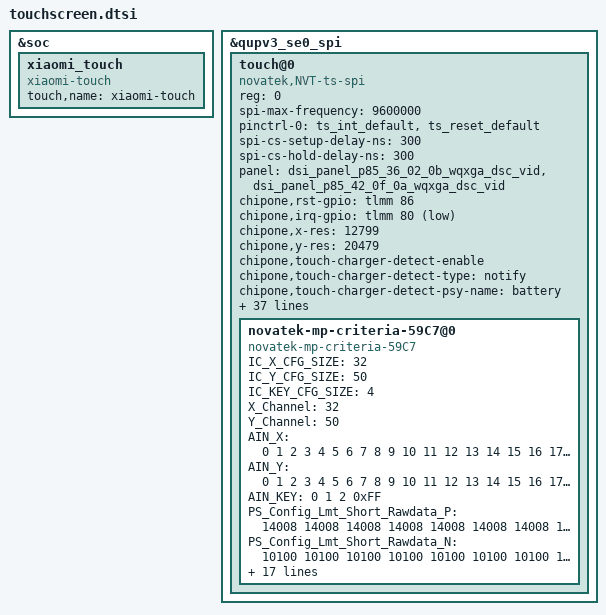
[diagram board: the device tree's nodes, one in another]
/*
 * Copyright (C) 2025 Novatek, Inc.
 *
 * $Revision$
 * $Date$
 *
 * This program is free software; you can redistribute it and/or modify
 * it under the terms of the GNU General Public License as published by
 * the Free Software Foundation; either version 2 of the License, or
 * (at your option) any later version.
 *
 * This program is distributed in the hope that it will be useful, but WITHOUT
 * ANY WARRANTY; without even the implied warranty of MERCHANTABILITY or
 * FITNESS FOR A PARTICULAR PURPOSE.  See the GNU General Public License for
 * more details.
 *
 */

&soc {
	xiaomi_touch {
		status = "okay";
		compatible = "xiaomi-touch";
		touch,name = "xiaomi-touch";
	};
};

&qupv3_se0_spi {
	status = "ok";

	/* Novatek device tree node */
	touch@0 {
		compatible = "novatek,NVT-ts-spi", "chipone-tddi";
		reg = <0>; //Same as CS ID
		status = "ok";

		spi-max-frequency = <9600000>;	//4800000,9600000,15000000,19200000
		pinctrl-names = "default";
		pinctrl-0 = <&ts_int_default>, <&ts_reset_default>;
		spi-cs-setup-delay-ns = <300>;
		spi-cs-hold-delay-ns = <300>;
		panel = <&dsi_panel_p85_36_02_0b_wqxga_dsc_vid &dsi_panel_p85_42_0f_0a_wqxga_dsc_vid>;

		/* chipone_icnl9951c */
		chipone,rst-gpio = <&tlmm 86 0x00>;
		chipone,irq-gpio = <&tlmm 80 0x2001>;
		//chipone,cs-gpio = <&tlmm 8 0>;
		chipone,x-res = <12799>;
		chipone,y-res = <20479>;

		/* Charger detect */
		chipone,touch-charger-detect-enable;
		chipone,touch-charger-detect-type = "notify"; /* notify, poll */
		chipone,touch-charger-detect-psy-name = "battery";
		chipone,touch-charger-detect-psp = "POWER_SUPPLY_PROP_STATUS";
		chipone,touch-charger-detect-psp-poll-interval = <1000>;

		/* Earjack detect */
		//chipone,touch-earjack-detect-enable;
		/* MTK:  /sys/bus/platform/drivers/Accdet_Driver/state,
		   Sprd: /sys/kernel/headset/state
		   QCOM: None, and disable it */
		//chipone,touch-earjack-state-filepath = "/sys/bus/platform/drivers/Accdet_Driver/state";
		//chipone,touch-earjack-poll-interval = <1000>;

		/* For tp selftest */
		chipone,test-reset-pin;
		chipone,test-int-pin;
		chipone,test-rawdata;
		chipone,test-rawdata-frames	  = <1>;
		chipone,rawdata-min			  = <1092>;
		chipone,rawdata-max			  = <3050>;
		chipone,test-noise;
		chipone,test-noise-frames		= <50>;
		chipone,noise-max				= <150>;
		chipone,test-open;
		chipone,open-min				 = <1750>;
		chipone,test-short;
		chipone,short-min				= <1550>;
		chipone,test-compensate-cap;
		chipone,compensate-cap-min	   = <1>;
		chipone,compensate-cap-max	   = <127>;

		/* gesture data test */
		chipone,test-gesture-rawdata;
		chipone,test-gesture-rawdata-frames = <1>;
		chipone,gesture-rawdata-min = <100>;
		chipone,gesture-rawdata-max = <10000>;

		chipone,test-gesture-lp-rawdata;
		chipone,test-gesture-lp-rawdata-frames = <1>;
		chipone,gesture-lp-rawdata-min = <100>;
		chipone,gesture-lp-rawdata-max = <10000>;

		chipone,test-gesture-noise;
		chipone,test-gesture-noise-frames = <50>;
		chipone,gesture-noise-max = <1000>;

		chipone,test-gesture-lp-noise;
		chipone,test-gesture-lp-noise-frames = <50>;
		chipone,gesture-lp-noise-max = <1000>;

		novatek,reset-gpio = <&tlmm 86 0x00>;
		novatek,irq-gpio = <&tlmm 80 0x2001>;

		//novatek,pen-support;

		//novatek,spi-rd-fast-addr = <0x03F310>;

		/* MP */
		novatek,mp-support-dt;

		novatek-mp-criteria-59C7@0 {
			#address-cells = <1>;
			#size-cells = <0>;
			compatible = "novatek-mp-criteria-59C7";

			/* MP Config */
			IC_X_CFG_SIZE = <32>;
			IC_Y_CFG_SIZE = <50>;
			IC_KEY_CFG_SIZE = <4>;
			X_Channel = <32>;
			Y_Channel = <50>;
			AIN_X = <0 1 2 3 4 5 6 7 8 9 10 11 12 13 14 15 16 17 18 19 20 21 22 23 24 25 26 27 28 29 30 31>;
			AIN_Y = <0 1 2 3 4 5 6 7 8 9 10 11 12 13 14 15 16 17 18 19 20 21 22 23 24 25 26 27 28 29 30 31 32 33 34 35 36 37 38 39 40 41 42 43 44 45 46 47 48 49>;
			AIN_KEY = <0 1 2 0xFF>;

			/* MP Criteria */
			PS_Config_Lmt_Short_Rawdata_P = <
				14008 14008 14008 14008 14008 14008 14008 14008 14008 14008 14008 14008 14008 14008 14008 14008 14008 14008 14008 14008 14008 14008 14008 14008 14008 14008 14008 14008 14008 14008 14008 14008
				14008 14008 14008 14008 14008 14008 14008 14008 14008 14008 14008 14008 14008 14008 14008 14008 14008 14008 14008 14008 14008 14008 14008 14008 14008 14008 14008 14008 14008 14008 14008 14008
				14008 14008 14008 14008 14008 14008 14008 14008 14008 14008 14008 14008 14008 14008 14008 14008 14008 14008 14008 14008 14008 14008 14008 14008 14008 14008 14008 14008 14008 14008 14008 14008
				14008 14008 14008 14008 14008 14008 14008 14008 14008 14008 14008 14008 14008 14008 14008 14008 14008 14008 14008 14008 14008 14008 14008 14008 14008 14008 14008 14008 14008 14008 14008 14008
				14008 14008 14008 14008 14008 14008 14008 14008 14008 14008 14008 14008 14008 14008 14008 14008 14008 14008 14008 14008 14008 14008 14008 14008 14008 14008 14008 14008 14008 14008 14008 14008
				14008 14008 14008 14008 14008 14008 14008 14008 14008 14008 14008 14008 14008 14008 14008 14008 14008 14008 14008 14008 14008 14008 14008 14008 14008 14008 14008 14008 14008 14008 14008 14008
				14008 14008 14008 14008 14008 14008 14008 14008 14008 14008 14008 14008 14008 14008 14008 14008 14008 14008 14008 14008 14008 14008 14008 14008 14008 14008 14008 14008 14008 14008 14008 14008
				14008 14008 14008 14008 14008 14008 14008 14008 14008 14008 14008 14008 14008 14008 14008 14008 14008 14008 14008 14008 14008 14008 14008 14008 14008 14008 14008 14008 14008 14008 14008 14008
				14008 14008 14008 14008 14008 14008 14008 14008 14008 14008 14008 14008 14008 14008 14008 14008 14008 14008 14008 14008 14008 14008 14008 14008 14008 14008 14008 14008 14008 14008 14008 14008
				14008 14008 14008 14008 14008 14008 14008 14008 14008 14008 14008 14008 14008 14008 14008 14008 14008 14008 14008 14008 14008 14008 14008 14008 14008 14008 14008 14008 14008 14008 14008 14008
				14008 14008 14008 14008 14008 14008 14008 14008 14008 14008 14008 14008 14008 14008 14008 14008 14008 14008 14008 14008 14008 14008 14008 14008 14008 14008 14008 14008 14008 14008 14008 14008
				14008 14008 14008 14008 14008 14008 14008 14008 14008 14008 14008 14008 14008 14008 14008 14008 14008 14008 14008 14008 14008 14008 14008 14008 14008 14008 14008 14008 14008 14008 14008 14008
				14008 14008 14008 14008 14008 14008 14008 14008 14008 14008 14008 14008 14008 14008 14008 14008 14008 14008 14008 14008 14008 14008 14008 14008 14008 14008 14008 14008 14008 14008 14008 14008
				14008 14008 14008 14008 14008 14008 14008 14008 14008 14008 14008 14008 14008 14008 14008 14008 14008 14008 14008 14008 14008 14008 14008 14008 14008 14008 14008 14008 14008 14008 14008 14008
				14008 14008 14008 14008 14008 14008 14008 14008 14008 14008 14008 14008 14008 14008 14008 14008 14008 14008 14008 14008 14008 14008 14008 14008 14008 14008 14008 14008 14008 14008 14008 14008
				14008 14008 14008 14008 14008 14008 14008 14008 14008 14008 14008 14008 14008 14008 14008 14008 14008 14008 14008 14008 14008 14008 14008 14008 14008 14008 14008 14008 14008 14008 14008 14008
				14008 14008 14008 14008 14008 14008 14008 14008 14008 14008 14008 14008 14008 14008 14008 14008 14008 14008 14008 14008 14008 14008 14008 14008 14008 14008 14008 14008 14008 14008 14008 14008
				14008 14008 14008 14008 14008 14008 14008 14008 14008 14008 14008 14008 14008 14008 14008 14008 14008 14008 14008 14008 14008 14008 14008 14008 14008 14008 14008 14008 14008 14008 14008 14008
				14008 14008 14008 14008 14008 14008 14008 14008 14008 14008 14008 14008 14008 14008 14008 14008 14008 14008 14008 14008 14008 14008 14008 14008 14008 14008 14008 14008 14008 14008 14008 14008
				14008 14008 14008 14008 14008 14008 14008 14008 14008 14008 14008 14008 14008 14008 14008 14008 14008 14008 14008 14008 14008 14008 14008 14008 14008 14008 14008 14008 14008 14008 14008 14008
				14008 14008 14008 14008 14008 14008 14008 14008 14008 14008 14008 14008 14008 14008 14008 14008 14008 14008 14008 14008 14008 14008 14008 14008 14008 14008 14008 14008 14008 14008 14008 14008
				14008 14008 14008 14008 14008 14008 14008 14008 14008 14008 14008 14008 14008 14008 14008 14008 14008 14008 14008 14008 14008 14008 14008 14008 14008 14008 14008 14008 14008 14008 14008 14008
				14008 14008 14008 14008 14008 14008 14008 14008 14008 14008 14008 14008 14008 14008 14008 14008 14008 14008 14008 14008 14008 14008 14008 14008 14008 14008 14008 14008 14008 14008 14008 14008
				14008 14008 14008 14008 14008 14008 14008 14008 14008 14008 14008 14008 14008 14008 14008 14008 14008 14008 14008 14008 14008 14008 14008 14008 14008 14008 14008 14008 14008 14008 14008 14008
				14008 14008 14008 14008 14008 14008 14008 14008 14008 14008 14008 14008 14008 14008 14008 14008 14008 14008 14008 14008 14008 14008 14008 14008 14008 14008 14008 14008 14008 14008 14008 14008
				14008 14008 14008 14008 14008 14008 14008 14008 14008 14008 14008 14008 14008 14008 14008 14008 14008 14008 14008 14008 14008 14008 14008 14008 14008 14008 14008 14008 14008 14008 14008 14008
				14008 14008 14008 14008 14008 14008 14008 14008 14008 14008 14008 14008 14008 14008 14008 14008 14008 14008 14008 14008 14008 14008 14008 14008 14008 14008 14008 14008 14008 14008 14008 14008
				14008 14008 14008 14008 14008 14008 14008 14008 14008 14008 14008 14008 14008 14008 14008 14008 14008 14008 14008 14008 14008 14008 14008 14008 14008 14008 14008 14008 14008 14008 14008 14008
				14008 14008 14008 14008 14008 14008 14008 14008 14008 14008 14008 14008 14008 14008 14008 14008 14008 14008 14008 14008 14008 14008 14008 14008 14008 14008 14008 14008 14008 14008 14008 14008
				14008 14008 14008 14008 14008 14008 14008 14008 14008 14008 14008 14008 14008 14008 14008 14008 14008 14008 14008 14008 14008 14008 14008 14008 14008 14008 14008 14008 14008 14008 14008 14008
				14008 14008 14008 14008 14008 14008 14008 14008 14008 14008 14008 14008 14008 14008 14008 14008 14008 14008 14008 14008 14008 14008 14008 14008 14008 14008 14008 14008 14008 14008 14008 14008
				14008 14008 14008 14008 14008 14008 14008 14008 14008 14008 14008 14008 14008 14008 14008 14008 14008 14008 14008 14008 14008 14008 14008 14008 14008 14008 14008 14008 14008 14008 14008 14008
				14008 14008 14008 14008 14008 14008 14008 14008 14008 14008 14008 14008 14008 14008 14008 14008 14008 14008 14008 14008 14008 14008 14008 14008 14008 14008 14008 14008 14008 14008 14008 14008
				14008 14008 14008 14008 14008 14008 14008 14008 14008 14008 14008 14008 14008 14008 14008 14008 14008 14008 14008 14008 14008 14008 14008 14008 14008 14008 14008 14008 14008 14008 14008 14008
				14008 14008 14008 14008 14008 14008 14008 14008 14008 14008 14008 14008 14008 14008 14008 14008 14008 14008 14008 14008 14008 14008 14008 14008 14008 14008 14008 14008 14008 14008 14008 14008
				14008 14008 14008 14008 14008 14008 14008 14008 14008 14008 14008 14008 14008 14008 14008 14008 14008 14008 14008 14008 14008 14008 14008 14008 14008 14008 14008 14008 14008 14008 14008 14008
				14008 14008 14008 14008 14008 14008 14008 14008 14008 14008 14008 14008 14008 14008 14008 14008 14008 14008 14008 14008 14008 14008 14008 14008 14008 14008 14008 14008 14008 14008 14008 14008
				14008 14008 14008 14008 14008 14008 14008 14008 14008 14008 14008 14008 14008 14008 14008 14008 14008 14008 14008 14008 14008 14008 14008 14008 14008 14008 14008 14008 14008 14008 14008 14008
				14008 14008 14008 14008 14008 14008 14008 14008 14008 14008 14008 14008 14008 14008 14008 14008 14008 14008 14008 14008 14008 14008 14008 14008 14008 14008 14008 14008 14008 14008 14008 14008
				14008 14008 14008 14008 14008 14008 14008 14008 14008 14008 14008 14008 14008 14008 14008 14008 14008 14008 14008 14008 14008 14008 14008 14008 14008 14008 14008 14008 14008 14008 14008 14008
				14008 14008 14008 14008 14008 14008 14008 14008 14008 14008 14008 14008 14008 14008 14008 14008 14008 14008 14008 14008 14008 14008 14008 14008 14008 14008 14008 14008 14008 14008 14008 14008
				14008 14008 14008 14008 14008 14008 14008 14008 14008 14008 14008 14008 14008 14008 14008 14008 14008 14008 14008 14008 14008 14008 14008 14008 14008 14008 14008 14008 14008 14008 14008 14008
				14008 14008 14008 14008 14008 14008 14008 14008 14008 14008 14008 14008 14008 14008 14008 14008 14008 14008 14008 14008 14008 14008 14008 14008 14008 14008 14008 14008 14008 14008 14008 14008
				14008 14008 14008 14008 14008 14008 14008 14008 14008 14008 14008 14008 14008 14008 14008 14008 14008 14008 14008 14008 14008 14008 14008 14008 14008 14008 14008 14008 14008 14008 14008 14008
				14008 14008 14008 14008 14008 14008 14008 14008 14008 14008 14008 14008 14008 14008 14008 14008 14008 14008 14008 14008 14008 14008 14008 14008 14008 14008 14008 14008 14008 14008 14008 14008
				14008 14008 14008 14008 14008 14008 14008 14008 14008 14008 14008 14008 14008 14008 14008 14008 14008 14008 14008 14008 14008 14008 14008 14008 14008 14008 14008 14008 14008 14008 14008 14008
				14008 14008 14008 14008 14008 14008 14008 14008 14008 14008 14008 14008 14008 14008 14008 14008 14008 14008 14008 14008 14008 14008 14008 14008 14008 14008 14008 14008 14008 14008 14008 14008
				14008 14008 14008 14008 14008 14008 14008 14008 14008 14008 14008 14008 14008 14008 14008 14008 14008 14008 14008 14008 14008 14008 14008 14008 14008 14008 14008 14008 14008 14008 14008 14008
				14008 14008 14008 14008 14008 14008 14008 14008 14008 14008 14008 14008 14008 14008 14008 14008 14008 14008 14008 14008 14008 14008 14008 14008 14008 14008 14008 14008 14008 14008 14008 14008
				14008 14008 14008 14008 14008 14008 14008 14008 14008 14008 14008 14008 14008 14008 14008 14008 14008 14008 14008 14008 14008 14008 14008 14008 14008 14008 14008 14008 14008 14008 14008 14008
				14008 14008 14008>;

			PS_Config_Lmt_Short_Rawdata_N = <
				10100 10100 10100 10100 10100 10100 10100 10100 10100 10100 10100 10100 10100 10100 10100 10100 10100 10100 10100 10100 10100 10100 10100 10100 10100 10100 10100 10100 10100 10100 10100 10100
				10100 10100 10100 10100 10100 10100 10100 10100 10100 10100 10100 10100 10100 10100 10100 10100 10100 10100 10100 10100 10100 10100 10100 10100 10100 10100 10100 10100 10100 10100 10100 10100
				10100 10100 10100 10100 10100 10100 10100 10100 10100 10100 10100 10100 10100 10100 10100 10100 10100 10100 10100 10100 10100 10100 10100 10100 10100 10100 10100 10100 10100 10100 10100 10100
				10100 10100 10100 10100 10100 10100 10100 10100 10100 10100 10100 10100 10100 10100 10100 10100 10100 10100 10100 10100 10100 10100 10100 10100 10100 10100 10100 10100 10100 10100 10100 10100
				10100 10100 10100 10100 10100 10100 10100 10100 10100 10100 10100 10100 10100 10100 10100 10100 10100 10100 10100 10100 10100 10100 10100 10100 10100 10100 10100 10100 10100 10100 10100 10100
				10100 10100 10100 10100 10100 10100 10100 10100 10100 10100 10100 10100 10100 10100 10100 10100 10100 10100 10100 10100 10100 10100 10100 10100 10100 10100 10100 10100 10100 10100 10100 10100
				10100 10100 10100 10100 10100 10100 10100 10100 10100 10100 10100 10100 10100 10100 10100 10100 10100 10100 10100 10100 10100 10100 10100 10100 10100 10100 10100 10100 10100 10100 10100 10100
				10100 10100 10100 10100 10100 10100 10100 10100 10100 10100 10100 10100 10100 10100 10100 10100 10100 10100 10100 10100 10100 10100 10100 10100 10100 10100 10100 10100 10100 10100 10100 10100
				10100 10100 10100 10100 10100 10100 10100 10100 10100 10100 10100 10100 10100 10100 10100 10100 10100 10100 10100 10100 10100 10100 10100 10100 10100 10100 10100 10100 10100 10100 10100 10100
				10100 10100 10100 10100 10100 10100 10100 10100 10100 10100 10100 10100 10100 10100 10100 10100 10100 10100 10100 10100 10100 10100 10100 10100 10100 10100 10100 10100 10100 10100 10100 10100
				10100 10100 10100 10100 10100 10100 10100 10100 10100 10100 10100 10100 10100 10100 10100 10100 10100 10100 10100 10100 10100 10100 10100 10100 10100 10100 10100 10100 10100 10100 10100 10100
				10100 10100 10100 10100 10100 10100 10100 10100 10100 10100 10100 10100 10100 10100 10100 10100 10100 10100 10100 10100 10100 10100 10100 10100 10100 10100 10100 10100 10100 10100 10100 10100
				10100 10100 10100 10100 10100 10100 10100 10100 10100 10100 10100 10100 10100 10100 10100 10100 10100 10100 10100 10100 10100 10100 10100 10100 10100 10100 10100 10100 10100 10100 10100 10100
				10100 10100 10100 10100 10100 10100 10100 10100 10100 10100 10100 10100 10100 10100 10100 10100 10100 10100 10100 10100 10100 10100 10100 10100 10100 10100 10100 10100 10100 10100 10100 10100
				10100 10100 10100 10100 10100 10100 10100 10100 10100 10100 10100 10100 10100 10100 10100 10100 10100 10100 10100 10100 10100 10100 10100 10100 10100 10100 10100 10100 10100 10100 10100 10100
				10100 10100 10100 10100 10100 10100 10100 10100 10100 10100 10100 10100 10100 10100 10100 10100 10100 10100 10100 10100 10100 10100 10100 10100 10100 10100 10100 10100 10100 10100 10100 10100
				10100 10100 10100 10100 10100 10100 10100 10100 10100 10100 10100 10100 10100 10100 10100 10100 10100 10100 10100 10100 10100 10100 10100 10100 10100 10100 10100 10100 10100 10100 10100 10100
				10100 10100 10100 10100 10100 10100 10100 10100 10100 10100 10100 10100 10100 10100 10100 10100 10100 10100 10100 10100 10100 10100 10100 10100 10100 10100 10100 10100 10100 10100 10100 10100
				10100 10100 10100 10100 10100 10100 10100 10100 10100 10100 10100 10100 10100 10100 10100 10100 10100 10100 10100 10100 10100 10100 10100 10100 10100 10100 10100 10100 10100 10100 10100 10100
				10100 10100 10100 10100 10100 10100 10100 10100 10100 10100 10100 10100 10100 10100 10100 10100 10100 10100 10100 10100 10100 10100 10100 10100 10100 10100 10100 10100 10100 10100 10100 10100
				10100 10100 10100 10100 10100 10100 10100 10100 10100 10100 10100 10100 10100 10100 10100 10100 10100 10100 10100 10100 10100 10100 10100 10100 10100 10100 10100 10100 10100 10100 10100 10100
				10100 10100 10100 10100 10100 10100 10100 10100 10100 10100 10100 10100 10100 10100 10100 10100 10100 10100 10100 10100 10100 10100 10100 10100 10100 10100 10100 10100 10100 10100 10100 10100
				10100 10100 10100 10100 10100 10100 10100 10100 10100 10100 10100 10100 10100 10100 10100 10100 10100 10100 10100 10100 10100 10100 10100 10100 10100 10100 10100 10100 10100 10100 10100 10100
				10100 10100 10100 10100 10100 10100 10100 10100 10100 10100 10100 10100 10100 10100 10100 10100 10100 10100 10100 10100 10100 10100 10100 10100 10100 10100 10100 10100 10100 10100 10100 10100
				10100 10100 10100 10100 10100 10100 10100 10100 10100 10100 10100 10100 10100 10100 10100 10100 10100 10100 10100 10100 10100 10100 10100 10100 10100 10100 10100 10100 10100 10100 10100 10100
				10100 10100 10100 10100 10100 10100 10100 10100 10100 10100 10100 10100 10100 10100 10100 10100 10100 10100 10100 10100 10100 10100 10100 10100 10100 10100 10100 10100 10100 10100 10100 10100
				10100 10100 10100 10100 10100 10100 10100 10100 10100 10100 10100 10100 10100 10100 10100 10100 10100 10100 10100 10100 10100 10100 10100 10100 10100 10100 10100 10100 10100 10100 10100 10100
				10100 10100 10100 10100 10100 10100 10100 10100 10100 10100 10100 10100 10100 10100 10100 10100 10100 10100 10100 10100 10100 10100 10100 10100 10100 10100 10100 10100 10100 10100 10100 10100
				10100 10100 10100 10100 10100 10100 10100 10100 10100 10100 10100 10100 10100 10100 10100 10100 10100 10100 10100 10100 10100 10100 10100 10100 10100 10100 10100 10100 10100 10100 10100 10100
				10100 10100 10100 10100 10100 10100 10100 10100 10100 10100 10100 10100 10100 10100 10100 10100 10100 10100 10100 10100 10100 10100 10100 10100 10100 10100 10100 10100 10100 10100 10100 10100
				10100 10100 10100 10100 10100 10100 10100 10100 10100 10100 10100 10100 10100 10100 10100 10100 10100 10100 10100 10100 10100 10100 10100 10100 10100 10100 10100 10100 10100 10100 10100 10100
				10100 10100 10100 10100 10100 10100 10100 10100 10100 10100 10100 10100 10100 10100 10100 10100 10100 10100 10100 10100 10100 10100 10100 10100 10100 10100 10100 10100 10100 10100 10100 10100
				10100 10100 10100 10100 10100 10100 10100 10100 10100 10100 10100 10100 10100 10100 10100 10100 10100 10100 10100 10100 10100 10100 10100 10100 10100 10100 10100 10100 10100 10100 10100 10100
				10100 10100 10100 10100 10100 10100 10100 10100 10100 10100 10100 10100 10100 10100 10100 10100 10100 10100 10100 10100 10100 10100 10100 10100 10100 10100 10100 10100 10100 10100 10100 10100
				10100 10100 10100 10100 10100 10100 10100 10100 10100 10100 10100 10100 10100 10100 10100 10100 10100 10100 10100 10100 10100 10100 10100 10100 10100 10100 10100 10100 10100 10100 10100 10100
				10100 10100 10100 10100 10100 10100 10100 10100 10100 10100 10100 10100 10100 10100 10100 10100 10100 10100 10100 10100 10100 10100 10100 10100 10100 10100 10100 10100 10100 10100 10100 10100
				10100 10100 10100 10100 10100 10100 10100 10100 10100 10100 10100 10100 10100 10100 10100 10100 10100 10100 10100 10100 10100 10100 10100 10100 10100 10100 10100 10100 10100 10100 10100 10100
				10100 10100 10100 10100 10100 10100 10100 10100 10100 10100 10100 10100 10100 10100 10100 10100 10100 10100 10100 10100 10100 10100 10100 10100 10100 10100 10100 10100 10100 10100 10100 10100
				10100 10100 10100 10100 10100 10100 10100 10100 10100 10100 10100 10100 10100 10100 10100 10100 10100 10100 10100 10100 10100 10100 10100 10100 10100 10100 10100 10100 10100 10100 10100 10100
				10100 10100 10100 10100 10100 10100 10100 10100 10100 10100 10100 10100 10100 10100 10100 10100 10100 10100 10100 10100 10100 10100 10100 10100 10100 10100 10100 10100 10100 10100 10100 10100
				10100 10100 10100 10100 10100 10100 10100 10100 10100 10100 10100 10100 10100 10100 10100 10100 10100 10100 10100 10100 10100 10100 10100 10100 10100 10100 10100 10100 10100 10100 10100 10100
				10100 10100 10100 10100 10100 10100 10100 10100 10100 10100 10100 10100 10100 10100 10100 10100 10100 10100 10100 10100 10100 10100 10100 10100 10100 10100 10100 10100 10100 10100 10100 10100
				10100 10100 10100 10100 10100 10100 10100 10100 10100 10100 10100 10100 10100 10100 10100 10100 10100 10100 10100 10100 10100 10100 10100 10100 10100 10100 10100 10100 10100 10100 10100 10100
				10100 10100 10100 10100 10100 10100 10100 10100 10100 10100 10100 10100 10100 10100 10100 10100 10100 10100 10100 10100 10100 10100 10100 10100 10100 10100 10100 10100 10100 10100 10100 10100
				10100 10100 10100 10100 10100 10100 10100 10100 10100 10100 10100 10100 10100 10100 10100 10100 10100 10100 10100 10100 10100 10100 10100 10100 10100 10100 10100 10100 10100 10100 10100 10100
				10100 10100 10100 10100 10100 10100 10100 10100 10100 10100 10100 10100 10100 10100 10100 10100 10100 10100 10100 10100 10100 10100 10100 10100 10100 10100 10100 10100 10100 10100 10100 10100
				10100 10100 10100 10100 10100 10100 10100 10100 10100 10100 10100 10100 10100 10100 10100 10100 10100 10100 10100 10100 10100 10100 10100 10100 10100 10100 10100 10100 10100 10100 10100 10100
				10100 10100 10100 10100 10100 10100 10100 10100 10100 10100 10100 10100 10100 10100 10100 10100 10100 10100 10100 10100 10100 10100 10100 10100 10100 10100 10100 10100 10100 10100 10100 10100
				10100 10100 10100 10100 10100 10100 10100 10100 10100 10100 10100 10100 10100 10100 10100 10100 10100 10100 10100 10100 10100 10100 10100 10100 10100 10100 10100 10100 10100 10100 10100 10100
				10100 10100 10100 10100 10100 10100 10100 10100 10100 10100 10100 10100 10100 10100 10100 10100 10100 10100 10100 10100 10100 10100 10100 10100 10100 10100 10100 10100 10100 10100 10100 10100
				10000 10000 10000>;

			PS_Config_Lmt_Open_Rawdata_P = <
				3406 3354 3319 3284 3263 3237 3217 3438 3108 3147 3174 3196 3217 3255 3304 3619 3305 3269 3230 3193 3172 3146 3128 3360 3100 3140 3165 3189 3212 3248 3294 3629
				3445 3399 3367 3335 3315 3287 3268 3479 3136 3167 3198 3220 3245 3280 3324 3615 3382 3345 3310 3270 3248 3223 3200 3429 3126 3160 3188 3212 3235 3273 3315 3619
				3479 3424 3391 3357 3340 3307 3287 3506 3196 3228 3262 3277 3304 3340 3385 3706 3423 3378 3339 3301 3283 3254 3234 3457 3175 3209 3241 3259 3287 3324 3367 3695
				3480 3437 3398 3370 3345 3319 3298 3511 3158 3192 3221 3241 3268 3304 3343 3640 3412 3371 3329 3296 3272 3249 3226 3454 3161 3195 3226 3245 3275 3311 3352 3654
				3485 3438 3396 3367 3345 3317 3301 3532 3189 3228 3255 3277 3304 3340 3382 3699 3406 3373 3326 3293 3269 3241 3226 3457 3157 3193 3219 3244 3269 3310 3350 3676
				3500 3455 3415 3380 3357 3326 3308 3528 3184 3223 3248 3275 3297 3335 3378 3668 3410 3373 3332 3293 3273 3247 3230 3450 3154 3193 3214 3241 3269 3305 3350 3651
				3492 3450 3413 3377 3350 3331 3310 3545 3175 3213 3235 3268 3291 3332 3370 3674 3406 3366 3326 3287 3262 3242 3221 3459 3168 3205 3228 3258 3280 3319 3357 3661
				3503 3457 3423 3387 3360 3335 3317 3532 3195 3224 3256 3282 3301 3339 3389 3696 3391 3352 3312 3273 3249 3228 3213 3429 3164 3196 3224 3249 3265 3304 3353 3679
				3479 3445 3406 3371 3349 3321 3308 3529 3191 3227 3256 3283 3301 3339 3380 3668 3398 3367 3325 3287 3266 3238 3228 3457 3156 3192 3223 3248 3266 3303 3345 3639
				3503 3471 3431 3394 3377 3347 3335 3553 3182 3216 3247 3263 3290 3328 3368 3657 3438 3410 3368 3325 3308 3279 3269 3500 3200 3235 3266 3283 3311 3350 3389 3679
				3507 3479 3436 3401 3381 3354 3345 3553 3224 3259 3289 3305 3336 3373 3413 3714 3419 3392 3347 3308 3289 3265 3256 3480 3186 3221 3249 3268 3296 3331 3373 3688
				3511 3480 3444 3408 3385 3363 3353 3570 3230 3268 3287 3314 3342 3378 3419 3695 3412 3382 3345 3303 3279 3259 3248 3478 3181 3214 3235 3262 3291 3326 3364 3636
				3458 3436 3398 3368 3345 3321 3311 3517 3238 3277 3298 3324 3350 3389 3431 3723 3387 3368 3325 3291 3265 3242 3235 3447 3200 3237 3258 3284 3311 3352 3392 3690
				3480 3466 3424 3388 3368 3347 3331 3541 3217 3252 3276 3305 3321 3371 3408 3665 3422 3403 3359 3318 3298 3282 3263 3492 3202 3231 3259 3287 3301 3350 3391 3665
				3529 3508 3471 3431 3412 3388 3373 3587 3252 3283 3308 3335 3354 3392 3443 3727 3413 3394 3352 3311 3289 3266 3254 3486 3234 3266 3294 3321 3338 3375 3426 3724
				3468 3452 3413 3374 3354 3331 3318 3517 3227 3263 3289 3307 3336 3371 3415 3686 3443 3427 3384 3343 3324 3301 3284 3504 3203 3240 3266 3284 3311 3347 3388 3674
				3515 3501 3459 3422 3401 3373 3367 3581 3228 3263 3291 3310 3335 3373 3416 3702 3429 3416 3370 3329 3308 3283 3277 3513 3210 3247 3272 3291 3321 3356 3396 3693
				3483 3471 3429 3391 3373 3343 3340 3538 3235 3270 3287 3315 3343 3375 3417 3681 3415 3403 3359 3319 3298 3269 3269 3476 3223 3255 3273 3303 3329 3364 3406 3681
				3499 3485 3450 3413 3387 3364 3357 3570 3247 3284 3305 3331 3357 3395 3441 3710 3447 3436 3396 3356 3329 3308 3303 3522 3231 3270 3290 3314 3336 3377 3417 3703
				3511 3501 3455 3427 3399 3377 3353 3569 3228 3258 3284 3310 3332 3373 3419 3681 3420 3409 3363 3329 3303 3282 3256 3471 3223 3248 3276 3301 3324 3363 3406 3682
				3521 3518 3478 3441 3419 3398 3373 3599 3251 3279 3307 3331 3356 3398 3440 3707 3451 3447 3402 3364 3345 3322 3294 3539 3224 3251 3276 3301 3326 3364 3408 3664
				3520 3517 3475 3438 3419 3385 3366 3584 3282 3317 3342 3363 3387 3427 3469 3739 3450 3448 3402 3366 3342 3314 3293 3521 3234 3272 3297 3317 3340 3380 3423 3704
				3480 3483 3447 3410 3392 3361 3342 3560 3294 3331 3354 3375 3399 3440 3478 3730 3409 3415 3373 3333 3311 3283 3265 3483 3265 3298 3322 3346 3370 3410 3447 3697
				3528 3535 3497 3458 3438 3409 3387 3619 3291 3329 3352 3371 3405 3438 3473 3724 3454 3461 3423 3385 3364 3333 3314 3556 3245 3283 3304 3325 3357 3387 3422 3678
				3513 3507 3497 3462 3436 3413 3391 3615 3319 3356 3375 3399 3429 3469 3479 3760 3437 3434 3419 3380 3350 3331 3307 3535 3290 3324 3346 3367 3399 3440 3450 3746
				3489 3480 3458 3431 3402 3378 3352 3553 3307 3340 3363 3392 3415 3457 3476 3725 3451 3443 3422 3391 3361 3338 3314 3528 3269 3307 3325 3354 3374 3416 3431 3683
				3539 3541 3525 3490 3469 3444 3422 3651 3301 3333 3350 3380 3403 3443 3459 3717 3423 3427 3410 3374 3350 3331 3305 3548 3272 3307 3326 3356 3378 3419 3430 3702
				3496 3499 3487 3448 3430 3405 3377 3594 3307 3340 3368 3389 3412 3450 3462 3696 3431 3436 3422 3384 3361 3338 3310 3534 3248 3282 3311 3332 3350 3395 3403 3653
				3500 3504 3494 3458 3440 3412 3388 3622 3291 3326 3350 3373 3396 3438 3448 3692 3482 3486 3475 3436 3412 3389 3363 3608 3273 3305 3333 3357 3378 3422 3430 3700
				3492 3494 3489 3450 3429 3406 3385 3591 3308 3356 3366 3388 3420 3458 3455 3711 3419 3424 3415 3378 3353 3329 3312 3543 3283 3333 3339 3363 3392 3433 3430 3699
				3532 3531 3531 3492 3469 3441 3422 3646 3329 3382 3391 3410 3440 3478 3479 3727 3469 3472 3469 3429 3405 3380 3361 3597 3262 3319 3328 3347 3378 3417 3416 3686
				3507 3503 3504 3471 3444 3422 3402 3605 3335 3384 3391 3419 3443 3483 3485 3746 3422 3426 3422 3384 3360 3336 3315 3536 3304 3352 3356 3387 3408 3448 3447 3725
				3490 3489 3494 3464 3438 3419 3394 3601 3342 3389 3396 3424 3443 3479 3476 3721 3434 3434 3441 3405 3380 3363 3335 3552 3322 3370 3373 3405 3426 3458 3454 3727
				3517 3511 3520 3493 3466 3450 3420 3641 3338 3384 3396 3416 3441 3472 3471 3716 3450 3451 3452 3423 3396 3380 3353 3592 3300 3345 3357 3380 3402 3436 3430 3660
				3527 3534 3531 3506 3487 3466 3434 3646 3328 3373 3388 3413 3433 3461 3458 3721 3408 3419 3410 3384 3366 3345 3317 3549 3361 3403 3415 3440 3458 3489 3485 3756
				3511 3517 3522 3489 3471 3448 3420 3637 3349 3399 3406 3429 3450 3472 3469 3713 3440 3450 3452 3419 3402 3380 3350 3576 3311 3364 3367 3392 3413 3440 3434 3690
				3500 3497 3504 3479 3457 3434 3412 3616 3377 3426 3436 3457 3485 3506 3497 3766 3447 3445 3450 3423 3398 3374 3352 3576 3335 3384 3389 3413 3441 3465 3454 3728
				3515 3511 3520 3499 3475 3450 3426 3634 3398 3441 3451 3471 3494 3513 3511 3759 3433 3433 3436 3413 3389 3367 3343 3555 3331 3374 3382 3405 3431 3455 3450 3700
				3539 3535 3541 3525 3501 3483 3458 3667 3381 3422 3430 3458 3480 3494 3493 3752 3461 3457 3461 3445 3420 3402 3377 3595 3354 3396 3403 3430 3452 3472 3468 3742
				3531 3527 3531 3517 3494 3476 3447 3658 3356 3395 3403 3431 3457 3466 3464 3699 3469 3466 3472 3455 3430 3413 3387 3608 3345 3387 3396 3422 3447 3458 3454 3700
				3555 3559 3556 3545 3527 3503 3475 3693 3387 3429 3440 3465 3487 3497 3497 3748 3485 3489 3487 3473 3451 3427 3401 3625 3328 3367 3382 3406 3429 3441 3438 3714
				3492 3496 3499 3483 3466 3444 3416 3618 3375 3412 3429 3454 3476 3489 3483 3725 3455 3459 3462 3445 3427 3405 3374 3595 3346 3387 3401 3426 3450 3462 3452 3709
				3562 3556 3560 3556 3528 3506 3480 3700 3367 3412 3420 3444 3472 3478 3469 3717 3478 3475 3478 3471 3444 3419 3395 3625 3367 3409 3419 3440 3471 3479 3471 3725
				3522 3521 3524 3520 3494 3471 3450 3650 3392 3431 3445 3469 3492 3497 3492 3737 3444 3443 3443 3438 3413 3391 3366 3585 3370 3410 3422 3451 3473 3479 3475 3744
				3539 3535 3541 3536 3510 3486 3461 3675 3420 3455 3469 3496 3520 3517 3517 3749 3479 3476 3478 3475 3451 3424 3401 3626 3384 3422 3434 3462 3483 3485 3479 3731
				3528 3527 3531 3532 3508 3489 3464 3669 3423 3457 3478 3500 3532 3521 3518 3781 3440 3438 3440 3438 3415 3396 3371 3591 3408 3443 3462 3486 3518 3506 3501 3787
				3522 3520 3521 3532 3508 3487 3458 3669 3430 3466 3486 3508 3532 3522 3515 3776 3451 3452 3448 3458 3437 3416 3384 3602 3413 3450 3472 3493 3515 3507 3500 3774
				3545 3538 3535 3543 3528 3506 3476 3688 3405 3444 3461 3483 3503 3492 3492 3732 3452 3450 3441 3455 3436 3416 3387 3594 3388 3426 3441 3469 3485 3479 3473 3732
				3517 3514 3515 3521 3504 3483 3458 3658 3419 3455 3469 3497 3514 3506 3503 3755 3436 3441 3438 3441 3427 3409 3382 3597 3408 3445 3461 3486 3503 3494 3490 3772
				3487 3479 3482 3490 3473 3461 3431 3623 3364 3394 3410 3438 3454 3447 3444 3601 3384 3382 3382 3389 3371 3359 3333 3532 3342 3375 3388 3415 3427 3422 3417 3590
				5120 5120 5120>;

			PS_Config_Lmt_Open_Rawdata_N = <
				1460 1438 1423 1408 1399 1387 1379 1474 1332 1349 1360 1370 1379 1395 1416 1551 1417 1401 1384 1369 1360 1348 1340 1440 1328 1346 1357 1367 1376 1392 1412 1555
				1477 1457 1443 1429 1421 1409 1400 1491 1344 1357 1370 1380 1391 1406 1424 1549 1450 1433 1418 1402 1392 1381 1372 1469 1340 1354 1366 1376 1387 1403 1421 1551
				1491 1468 1453 1439 1432 1417 1409 1502 1370 1384 1398 1405 1416 1432 1451 1588 1467 1448 1431 1415 1407 1394 1386 1481 1361 1375 1389 1397 1409 1424 1443 1583
				1492 1473 1456 1444 1433 1423 1414 1505 1354 1368 1381 1389 1400 1416 1433 1560 1462 1445 1427 1412 1402 1393 1382 1480 1355 1369 1382 1391 1403 1419 1436 1566
				1493 1474 1456 1443 1433 1421 1415 1514 1367 1384 1395 1405 1416 1432 1450 1585 1460 1445 1426 1411 1401 1389 1382 1481 1353 1369 1379 1390 1401 1418 1436 1576
				1500 1481 1463 1448 1439 1426 1418 1512 1364 1381 1392 1403 1413 1429 1448 1572 1462 1445 1428 1411 1403 1391 1384 1478 1352 1369 1378 1389 1401 1417 1436 1565
				1496 1478 1463 1447 1436 1427 1418 1519 1361 1377 1387 1400 1411 1428 1444 1574 1460 1442 1426 1409 1398 1390 1381 1483 1358 1373 1384 1396 1406 1423 1439 1569
				1501 1481 1467 1451 1440 1429 1421 1514 1369 1382 1396 1406 1415 1431 1453 1584 1453 1436 1420 1403 1393 1384 1377 1469 1356 1370 1382 1393 1399 1416 1437 1577
				1491 1477 1460 1445 1435 1423 1418 1513 1367 1383 1396 1407 1415 1431 1448 1572 1456 1443 1425 1409 1400 1388 1384 1481 1352 1368 1381 1392 1400 1415 1433 1559
				1501 1487 1471 1454 1447 1435 1429 1523 1364 1378 1391 1399 1410 1426 1444 1567 1474 1462 1444 1425 1418 1405 1401 1500 1372 1387 1400 1407 1419 1436 1453 1577
				1503 1491 1472 1457 1449 1438 1433 1523 1382 1397 1409 1417 1430 1445 1463 1592 1465 1454 1435 1418 1409 1399 1396 1492 1366 1381 1393 1400 1412 1427 1445 1580
				1505 1492 1476 1460 1451 1441 1437 1530 1384 1400 1409 1420 1432 1448 1465 1583 1462 1450 1433 1415 1405 1397 1392 1490 1363 1378 1387 1398 1411 1426 1442 1558
				1482 1472 1456 1444 1433 1423 1419 1507 1388 1405 1414 1424 1436 1453 1471 1595 1451 1444 1425 1411 1399 1390 1387 1477 1372 1387 1396 1408 1419 1436 1454 1582
				1492 1486 1468 1452 1444 1435 1427 1517 1379 1394 1404 1417 1423 1445 1460 1571 1466 1459 1439 1422 1414 1406 1399 1496 1372 1385 1397 1409 1415 1436 1453 1571
				1513 1504 1487 1471 1462 1452 1445 1537 1394 1407 1418 1429 1438 1454 1475 1597 1463 1454 1436 1419 1409 1400 1394 1494 1386 1400 1412 1423 1430 1447 1468 1596
				1486 1480 1463 1446 1438 1427 1422 1507 1383 1399 1409 1417 1430 1445 1463 1580 1475 1469 1450 1433 1424 1415 1408 1502 1373 1388 1400 1408 1419 1435 1452 1574
				1507 1501 1483 1466 1457 1445 1443 1535 1384 1399 1411 1418 1429 1445 1464 1586 1469 1464 1444 1427 1418 1407 1405 1505 1376 1391 1402 1411 1423 1438 1456 1583
				1493 1487 1469 1453 1445 1433 1432 1516 1387 1402 1409 1421 1433 1447 1465 1577 1463 1459 1439 1423 1414 1401 1401 1490 1381 1395 1403 1415 1427 1442 1460 1577
				1499 1493 1478 1463 1451 1442 1439 1530 1391 1408 1417 1427 1439 1455 1475 1590 1477 1472 1456 1438 1427 1418 1415 1510 1385 1402 1410 1420 1430 1447 1465 1587
				1505 1501 1481 1469 1457 1447 1437 1529 1384 1396 1408 1418 1428 1445 1465 1577 1466 1461 1441 1427 1415 1406 1396 1487 1381 1392 1404 1415 1424 1441 1460 1578
				1509 1508 1490 1475 1465 1456 1445 1543 1393 1405 1417 1427 1438 1456 1474 1589 1479 1477 1458 1442 1433 1424 1412 1517 1382 1393 1404 1415 1426 1442 1460 1570
				1508 1507 1489 1474 1465 1451 1442 1536 1406 1421 1432 1441 1451 1469 1487 1603 1478 1478 1458 1442 1432 1420 1411 1509 1386 1402 1413 1421 1432 1448 1467 1588
				1492 1493 1477 1462 1454 1441 1432 1526 1412 1427 1438 1447 1457 1474 1490 1598 1461 1463 1445 1429 1419 1407 1399 1493 1399 1414 1424 1434 1444 1462 1477 1585
				1512 1515 1499 1482 1474 1461 1451 1551 1411 1427 1436 1445 1459 1474 1489 1596 1480 1483 1467 1451 1442 1429 1420 1524 1391 1407 1416 1425 1439 1451 1466 1576
				1505 1503 1499 1484 1472 1463 1453 1549 1423 1438 1447 1457 1469 1487 1491 1612 1473 1472 1465 1448 1436 1427 1417 1515 1410 1424 1434 1443 1457 1474 1478 1606
				1495 1492 1482 1471 1458 1448 1436 1523 1417 1432 1441 1454 1463 1481 1490 1597 1479 1475 1466 1453 1441 1430 1420 1512 1401 1417 1425 1438 1446 1464 1471 1579
				1517 1517 1511 1496 1487 1476 1466 1565 1415 1429 1436 1448 1459 1475 1483 1593 1467 1469 1462 1446 1436 1427 1417 1520 1402 1417 1426 1438 1448 1465 1470 1586
				1498 1499 1495 1478 1470 1459 1447 1540 1417 1432 1444 1453 1462 1478 1484 1584 1471 1472 1466 1450 1441 1430 1418 1514 1392 1406 1419 1428 1436 1455 1459 1565
				1500 1502 1498 1482 1474 1462 1452 1552 1411 1426 1436 1445 1456 1474 1478 1582 1492 1494 1489 1472 1462 1453 1441 1546 1403 1417 1429 1439 1448 1466 1470 1586
				1496 1498 1495 1478 1469 1460 1451 1539 1418 1438 1442 1452 1466 1482 1481 1591 1465 1468 1463 1448 1437 1427 1420 1519 1407 1429 1431 1441 1454 1471 1470 1585
				1514 1513 1513 1496 1487 1475 1466 1562 1427 1450 1453 1462 1474 1490 1491 1597 1487 1488 1487 1469 1459 1448 1441 1541 1398 1423 1426 1435 1448 1465 1464 1580
				1503 1501 1502 1487 1476 1466 1458 1545 1429 1450 1453 1465 1475 1493 1493 1606 1466 1468 1466 1450 1440 1430 1421 1516 1416 1436 1438 1451 1460 1478 1477 1597
				1496 1495 1498 1484 1474 1465 1454 1543 1432 1453 1456 1468 1475 1491 1490 1595 1472 1472 1475 1459 1448 1441 1429 1522 1424 1444 1445 1459 1468 1482 1480 1597
				1507 1505 1508 1497 1486 1478 1466 1561 1430 1450 1456 1464 1475 1488 1487 1592 1478 1479 1480 1467 1456 1448 1437 1540 1414 1433 1439 1448 1458 1472 1470 1568
				1511 1514 1513 1502 1495 1486 1472 1562 1426 1445 1452 1463 1471 1483 1482 1595 1460 1465 1462 1450 1442 1433 1421 1521 1441 1459 1463 1474 1482 1495 1493 1610
				1505 1507 1510 1495 1487 1478 1466 1559 1435 1457 1460 1469 1478 1488 1487 1591 1474 1478 1480 1465 1458 1448 1436 1532 1419 1442 1443 1454 1463 1474 1472 1582
				1500 1499 1502 1491 1481 1472 1462 1550 1447 1468 1472 1481 1493 1502 1499 1614 1477 1477 1478 1467 1456 1446 1436 1532 1429 1450 1453 1463 1475 1485 1480 1598
				1507 1505 1508 1499 1489 1478 1468 1558 1456 1475 1479 1487 1498 1505 1505 1611 1471 1471 1472 1463 1453 1443 1433 1523 1427 1446 1450 1459 1471 1481 1478 1586
				1517 1515 1517 1511 1501 1493 1482 1571 1449 1466 1470 1482 1492 1498 1497 1608 1483 1481 1483 1477 1466 1458 1447 1541 1438 1456 1459 1470 1480 1488 1486 1604
				1513 1511 1513 1507 1498 1490 1477 1568 1438 1455 1459 1471 1481 1486 1484 1585 1487 1486 1488 1481 1470 1463 1451 1546 1433 1451 1456 1466 1477 1482 1480 1586
				1523 1525 1524 1519 1511 1501 1489 1583 1451 1469 1474 1485 1495 1499 1499 1606 1493 1495 1495 1489 1479 1469 1457 1553 1426 1443 1450 1460 1469 1475 1474 1592
				1496 1498 1499 1493 1486 1476 1464 1550 1447 1462 1469 1480 1490 1495 1493 1597 1481 1483 1484 1477 1469 1459 1446 1541 1434 1451 1457 1468 1478 1484 1480 1589
				1526 1524 1526 1524 1512 1502 1492 1586 1443 1462 1466 1476 1488 1490 1487 1593 1490 1489 1490 1487 1476 1465 1455 1553 1443 1461 1465 1474 1487 1491 1487 1597
				1510 1509 1510 1508 1498 1487 1478 1564 1454 1471 1477 1487 1496 1499 1496 1601 1476 1475 1475 1474 1463 1453 1442 1537 1444 1462 1466 1479 1489 1491 1489 1604
				1517 1515 1517 1516 1504 1494 1483 1575 1466 1481 1487 1498 1508 1507 1507 1607 1491 1490 1490 1489 1479 1468 1457 1554 1450 1466 1472 1484 1493 1493 1491 1599
				1512 1511 1513 1514 1504 1495 1484 1573 1467 1481 1490 1500 1514 1509 1508 1621 1474 1474 1474 1474 1463 1456 1445 1539 1460 1475 1484 1494 1508 1502 1501 1623
				1510 1508 1509 1514 1504 1495 1482 1573 1470 1486 1494 1504 1514 1510 1507 1618 1479 1480 1478 1482 1473 1464 1450 1544 1463 1478 1488 1497 1507 1503 1500 1618
				1519 1516 1515 1519 1512 1502 1490 1580 1459 1476 1483 1493 1501 1496 1496 1600 1480 1478 1475 1481 1472 1464 1451 1540 1452 1468 1475 1487 1493 1491 1489 1600
				1507 1506 1507 1509 1502 1493 1482 1568 1465 1481 1487 1499 1506 1502 1501 1609 1472 1475 1474 1475 1469 1461 1450 1541 1460 1477 1483 1494 1501 1498 1496 1616
				1495 1491 1492 1496 1489 1483 1471 1553 1442 1454 1462 1474 1480 1477 1476 1543 1450 1450 1450 1453 1445 1439 1429 1514 1432 1447 1452 1463 1469 1466 1465 1538
				(-511) (-511) (-511)>;

			PS_Config_Lmt_FW_Rawdata_P = <
				1123 1120 1117 1119 1119 1120 1123 1126 1120 1121 1126 1121 1120 1121 1126 1110 1123 1119 1120 1119 1120 1116 1119 1121 1116 1120 1114 1119 1123 1119 1116 1123
				1120 1126 1126 1120 1117 1113 1113 1116 1124 1114 1117 1123 1131 1119 1117 1123 1119 1117 1116 1123 1123 1120 1126 1123 1116 1124 1119 1113 1113 1117 1124 1117
				1112 1114 1116 1117 1121 1121 1124 1120 1117 1120 1120 1119 1120 1120 1120 1117 1123 1126 1126 1119 1113 1121 1128 1127 1127 1110 1124 1130 1126 1116 1117 1110
				1119 1117 1116 1117 1126 1123 1121 1124 1117 1123 1123 1119 1116 1119 1124 1120 1120 1121 1123 1123 1120 1119 1120 1116 1124 1127 1121 1120 1119 1120 1126 1119
				1117 1117 1117 1119 1119 1127 1121 1126 1117 1124 1120 1123 1121 1117 1121 1119 1124 1123 1124 1124 1117 1116 1114 1119 1126 1120 1121 1121 1121 1109 1117 1123
				1121 1121 1121 1119 1123 1119 1116 1119 1123 1120 1123 1121 1124 1121 1120 1116 1119 1126 1120 1119 1121 1124 1124 1124 1126 1117 1119 1117 1117 1120 1120 1120
				1123 1117 1120 1117 1119 1117 1120 1121 1127 1120 1116 1117 1117 1121 1123 1119 1124 1130 1128 1128 1119 1113 1113 1113 1124 1117 1119 1117 1119 1117 1121 1121
				1119 1114 1114 1114 1116 1117 1128 1119 1117 1120 1124 1120 1123 1114 1117 1119 1120 1121 1121 1120 1120 1117 1119 1116 1130 1121 1123 1120 1121 1119 1121 1117
				1120 1124 1117 1121 1131 1127 1124 1126 1119 1119 1117 1117 1120 1121 1121 1126 1123 1120 1117 1117 1114 1121 1126 1120 1121 1120 1119 1119 1117 1120 1130 1126
				1123 1121 1124 1127 1124 1121 1123 1117 1120 1126 1117 1121 1123 1124 1130 1114 1113 1116 1113 1121 1123 1121 1120 1121 1123 1121 1124 1127 1124 1124 1116 1121
				1123 1127 1121 1123 1121 1119 1126 1121 1116 1121 1112 1121 1121 1123 1123 1117 1120 1113 1113 1123 1123 1123 1123 1128 1126 1126 1121 1124 1124 1127 1126 1124
				1123 1119 1120 1127 1123 1121 1120 1126 1120 1121 1123 1126 1123 1123 1127 1114 1123 1114 1112 1113 1123 1123 1121 1124 1124 1121 1124 1124 1124 1121 1117 1124
				1116 1123 1121 1121 1130 1128 1130 1126 1126 1127 1123 1126 1124 1121 1120 1124 1113 1124 1116 1117 1116 1116 1112 1114 1121 1130 1126 1126 1126 1127 1124 1127
				1110 1113 1112 1112 1119 1119 1116 1116 1127 1120 1128 1128 1119 1127 1120 1120 1117 1113 1117 1127 1126 1128 1126 1116 1116 1116 1128 1126 1112 1126 1114 1121
				1114 1119 1116 1119 1116 1116 1120 1123 1123 1124 1116 1121 1112 1117 1116 1119 1124 1113 1121 1121 1117 1121 1117 1119 1117 1119 1121 1119 1117 1114 1121 1114
				1112 1123 1126 1124 1120 1123 1121 1127 1120 1117 1120 1117 1119 1114 1120 1121 1119 1113 1114 1121 1120 1123 1119 1112 1121 1117 1117 1120 1116 1114 1120 1124
				1124 1116 1117 1120 1117 1120 1120 1123 1120 1121 1123 1117 1117 1116 1117 1121 1120 1119 1117 1120 1126 1117 1116 1120 1123 1126 1124 1123 1123 1121 1121 1124
				1120 1117 1123 1126 1123 1120 1120 1130 1120 1123 1120 1119 1117 1117 1124 1124 1121 1120 1121 1128 1126 1126 1127 1127 1123 1121 1116 1117 1117 1114 1121 1119
				1120 1120 1121 1116 1124 1121 1121 1124 1119 1120 1119 1123 1117 1123 1114 1120 1116 1121 1119 1119 1121 1116 1116 1117 1113 1119 1121 1116 1119 1119 1112 1126
				1117 1126 1123 1120 1123 1124 1127 1119 1119 1120 1117 1120 1123 1114 1119 1124 1116 1114 1116 1124 1121 1124 1120 1123 1117 1113 1123 1126 1123 1127 1116 1120
				1123 1119 1113 1110 1119 1119 1123 1124 1124 1121 1121 1121 1124 1123 1124 1117 1117 1119 1119 1116 1117 1116 1119 1120 1123 1120 1121 1117 1117 1110 1114 1119
				1124 1116 1117 1124 1119 1119 1114 1112 1121 1119 1121 1121 1119 1117 1121 1119 1124 1117 1117 1120 1116 1124 1117 1120 1127 1130 1126 1124 1123 1127 1119 1120
				1119 1121 1120 1120 1117 1117 1124 1120 1121 1123 1123 1123 1124 1120 1120 1120 1124 1114 1113 1119 1116 1114 1121 1116 1117 1119 1124 1120 1117 1120 1124 1123
				1124 1119 1124 1124 1124 1114 1114 1117 1123 1120 1121 1127 1126 1124 1123 1113 1120 1113 1110 1128 1116 1110 1121 1117 1123 1128 1117 1121 1117 1119 1116 1127
				1117 1121 1116 1120 1121 1121 1120 1120 1124 1126 1127 1126 1120 1117 1121 1120 1124 1116 1121 1128 1113 1116 1117 1120 1114 1114 1110 1113 1126 1120 1113 1120
				1119 1117 1116 1120 1113 1119 1120 1119 1126 1123 1128 1120 1117 1120 1120 1117 1126 1124 1123 1123 1126 1123 1126 1124 1119 1112 1123 1124 1127 1120 1124 1121
				1120 1126 1120 1120 1123 1121 1117 1116 1113 1123 1119 1121 1123 1123 1123 1123 1120 1116 1119 1123 1126 1126 1124 1124 1120 1124 1124 1124 1120 1117 1116 1116
				1117 1120 1117 1117 1117 1120 1124 1119 1121 1124 1114 1120 1117 1117 1117 1121 1123 1119 1117 1119 1116 1119 1123 1121 1116 1117 1123 1121 1119 1126 1124 1120
				1119 1121 1119 1117 1121 1121 1124 1124 1117 1117 1130 1130 1126 1123 1124 1119 1121 1113 1117 1120 1116 1116 1117 1120 1124 1128 1117 1119 1116 1114 1119 1121
				1117 1117 1117 1114 1119 1117 1120 1123 1120 1123 1120 1120 1123 1120 1117 1120 1119 1116 1119 1120 1121 1119 1120 1121 1114 1116 1110 1116 1117 1119 1113 1123
				1114 1123 1119 1123 1123 1121 1124 1127 1124 1117 1119 1121 1114 1113 1126 1127 1126 1113 1110 1114 1119 1119 1116 1113 1112 1112 1117 1119 1124 1124 1117 1121
				1128 1114 1119 1119 1114 1117 1117 1120 1123 1119 1121 1116 1116 1110 1114 1128 1117 1130 1121 1121 1117 1119 1117 1124 1116 1126 1123 1126 1121 1123 1126 1114
				1123 1124 1126 1131 1130 1124 1120 1117 1124 1123 1124 1123 1121 1123 1123 1109 1126 1119 1117 1121 1120 1120 1128 1124 1116 1123 1117 1121 1123 1120 1126 1119
				1121 1128 1131 1131 1127 1134 1117 1117 1127 1121 1117 1117 1119 1119 1119 1120 1119 1119 1121 1123 1128 1119 1127 1127 1117 1126 1123 1126 1123 1124 1124 1116
				1120 1121 1116 1121 1124 1124 1123 1120 1124 1126 1124 1127 1126 1128 1124 1116 1114 1116 1123 1121 1120 1114 1127 1123 1120 1119 1114 1110 1114 1110 1113 1117
				1124 1123 1117 1112 1113 1114 1123 1121 1123 1119 1117 1119 1119 1116 1117 1124 1121 1123 1117 1114 1127 1126 1117 1121 1121 1117 1116 1114 1117 1119 1121 1116
				1123 1126 1121 1124 1127 1126 1116 1120 1124 1128 1126 1126 1126 1124 1123 1114 1128 1120 1117 1114 1116 1116 1117 1120 1119 1121 1121 1121 1116 1114 1126 1123
				1121 1123 1117 1121 1119 1119 1116 1114 1126 1119 1119 1121 1124 1121 1123 1117 1128 1112 1113 1117 1116 1114 1117 1119 1116 1117 1114 1120 1117 1117 1119 1126
				1123 1120 1114 1119 1120 1126 1116 1117 1114 1123 1120 1114 1119 1113 1119 1123 1120 1116 1114 1117 1117 1119 1119 1120 1123 1126 1124 1123 1119 1119 1117 1126
				1116 1117 1116 1117 1120 1113 1121 1126 1121 1124 1123 1121 1123 1121 1121 1119 1123 1120 1119 1121 1116 1120 1117 1123 1117 1113 1114 1113 1117 1117 1120 1124
				1116 1121 1127 1124 1123 1124 1127 1113 1123 1128 1124 1126 1123 1120 1121 1124 1123 1121 1120 1123 1121 1121 1123 1120 1127 1130 1130 1124 1126 1121 1120 1121
				1124 1120 1121 1114 1121 1113 1120 1120 1130 1128 1127 1126 1128 1124 1126 1119 1121 1128 1123 1114 1124 1121 1121 1116 1120 1123 1116 1117 1121 1121 1119 1116
				1124 1120 1119 1120 1116 1117 1119 1123 1123 1124 1120 1119 1121 1124 1120 1121 1114 1127 1123 1121 1123 1117 1119 1121 1130 1123 1124 1127 1114 1110 1124 1112
				1117 1120 1121 1124 1121 1126 1123 1116 1123 1123 1121 1121 1120 1116 1121 1116 1126 1123 1120 1119 1121 1120 1123 1120 1121 1121 1119 1123 1121 1124 1117 1120
				1121 1117 1121 1121 1124 1126 1114 1123 1119 1120 1123 1119 1114 1114 1114 1116 1113 1127 1124 1127 1128 1131 1114 1123 1116 1114 1117 1121 1121 1119 1121 1123
				1119 1123 1120 1124 1121 1121 1124 1117 1116 1113 1112 1113 1121 1116 1117 1117 1119 1123 1114 1123 1120 1120 1128 1114 1119 1120 1121 1119 1124 1119 1119 1127
				1126 1117 1117 1120 1116 1120 1117 1127 1126 1121 1123 1124 1124 1123 1123 1126 1119 1117 1116 1123 1121 1124 1113 1124 1121 1119 1114 1116 1123 1120 1121 1131
				1114 1120 1114 1120 1120 1119 1119 1123 1116 1119 1116 1117 1117 1120 1120 1121 1123 1121 1114 1117 1113 1121 1123 1119 1117 1116 1116 1120 1124 1121 1121 1120
				1117 1121 1119 1121 1113 1120 1120 1114 1120 1128 1128 1120 1117 1117 1119 1126 1121 1124 1117 1120 1119 1116 1120 1123 1120 1120 1120 1120 1121 1124 1130 1124
				1113 1121 1121 1126 1121 1126 1117 1128 1116 1119 1116 1120 1121 1124 1126 1124 1126 1117 1109 1120 1119 1117 1119 1117 1119 1117 1116 1117 1123 1121 1123 1120
				3840 3840 3840>;

			PS_Config_Lmt_FW_Rawdata_N = <
				481 480 479 479 479 480 481 482 480 481 482 481 480 481 482 476 481 479 480 479 480 478 479 481 478 480 478 479 481 479 478 481
				480 482 482 480 479 477 477 478 482 478 479 481 485 479 479 481 479 479 478 481 481 480 482 481 478 482 479 477 477 479 482 479
				476 478 478 479 481 481 482 480 479 480 480 479 480 480 480 479 481 482 482 479 477 481 484 483 483 476 482 484 482 478 479 476
				479 479 478 479 482 481 481 482 479 481 481 479 478 479 482 480 480 481 481 481 480 479 480 478 482 483 481 480 479 480 482 479
				479 479 479 479 479 483 481 482 479 482 480 481 481 479 481 479 482 481 482 482 479 478 478 479 482 480 481 481 481 475 479 481
				481 481 481 479 481 479 478 479 481 480 481 481 482 481 480 478 479 482 480 479 481 482 482 482 482 479 479 479 479 480 480 480
				481 479 480 479 479 479 480 481 483 480 478 479 479 481 481 479 482 484 484 484 479 477 477 477 482 479 479 479 479 479 481 481
				479 478 478 478 478 479 484 479 479 480 482 480 481 478 479 479 480 481 481 480 480 479 479 478 484 481 481 480 481 479 481 479
				480 482 479 481 485 483 482 482 479 479 479 479 480 481 481 482 481 480 479 479 478 481 482 480 481 480 479 479 479 480 484 482
				481 481 482 483 482 481 481 479 480 482 479 481 481 482 484 478 477 478 477 481 481 481 480 481 481 481 482 483 482 482 478 481
				481 483 481 481 481 479 482 481 478 481 476 481 481 481 481 479 480 477 477 481 481 481 481 484 482 482 481 482 482 483 482 482
				481 479 480 483 481 481 480 482 480 481 481 482 481 481 483 478 481 478 476 477 481 481 481 482 482 481 482 482 482 481 479 482
				478 481 481 481 484 484 484 482 482 483 481 482 482 481 480 482 477 482 478 479 478 478 476 478 481 484 482 482 482 483 482 483
				476 477 476 476 479 479 478 478 483 480 484 484 479 483 480 480 479 477 479 483 482 484 482 478 478 478 484 482 476 482 478 481
				478 479 478 479 478 478 480 481 481 482 478 481 476 479 478 479 482 477 481 481 479 481 479 479 479 479 481 479 479 478 481 478
				476 481 482 482 480 481 481 483 480 479 480 479 479 478 480 481 479 477 478 481 480 481 479 476 481 479 479 480 478 478 480 482
				482 478 479 480 479 480 480 481 480 481 481 479 479 478 479 481 480 479 479 480 482 479 478 480 481 482 482 481 481 481 481 482
				480 479 481 482 481 480 480 484 480 481 480 479 479 479 482 482 481 480 481 484 482 482 483 483 481 481 478 479 479 478 481 479
				480 480 481 478 482 481 481 482 479 480 479 481 479 481 478 480 478 481 479 479 481 478 478 479 477 479 481 478 479 479 476 482
				479 482 481 480 481 482 483 479 479 480 479 480 481 478 479 482 478 478 478 482 481 482 480 481 479 477 481 482 481 483 478 480
				481 479 477 476 479 479 481 482 482 481 481 481 482 481 482 479 479 479 479 478 479 478 479 480 481 480 481 479 479 476 478 479
				482 478 479 482 479 479 478 476 481 479 481 481 479 479 481 479 482 479 479 480 478 482 479 480 483 484 482 482 481 483 479 480
				479 481 480 480 479 479 482 480 481 481 481 481 482 480 480 480 482 478 477 479 478 478 481 478 479 479 482 480 479 480 482 481
				482 479 482 482 482 478 478 479 481 480 481 483 482 482 481 477 480 477 476 484 478 476 481 479 481 484 479 481 479 479 478 483
				479 481 478 480 481 481 480 480 482 482 483 482 480 479 481 480 482 478 481 484 477 478 479 480 478 478 476 477 482 480 477 480
				479 479 478 480 477 479 480 479 482 481 484 480 479 480 480 479 482 482 481 481 482 481 482 482 479 476 481 482 483 480 482 481
				480 482 480 480 481 481 479 478 477 481 479 481 481 481 481 481 480 478 479 481 482 482 482 482 480 482 482 482 480 479 478 478
				479 480 479 479 479 480 482 479 481 482 478 480 479 479 479 481 481 479 479 479 478 479 481 481 478 479 481 481 479 482 482 480
				479 481 479 479 481 481 482 482 479 479 484 484 482 481 482 479 481 477 479 480 478 478 479 480 482 484 479 479 478 478 479 481
				479 479 479 478 479 479 480 481 480 481 480 480 481 480 479 480 479 478 479 480 481 479 480 481 478 478 476 478 479 479 477 481
				478 481 479 481 481 481 482 483 482 479 479 481 478 477 482 483 482 477 476 478 479 479 478 477 476 476 479 479 482 482 479 481
				484 478 479 479 478 479 479 480 481 479 481 478 478 476 478 484 479 484 481 481 479 479 479 482 478 482 481 482 481 481 482 478
				481 482 482 485 484 482 480 479 482 481 482 481 481 481 481 475 482 479 479 481 480 480 484 482 478 481 479 481 481 480 482 479
				481 484 485 485 483 486 479 479 483 481 479 479 479 479 479 480 479 479 481 481 484 479 483 483 479 482 481 482 481 482 482 478
				480 481 478 481 482 482 481 480 482 482 482 483 482 484 482 478 478 478 481 481 480 478 483 481 480 479 478 476 478 476 477 479
				482 481 479 476 477 478 481 481 481 479 479 479 479 478 479 482 481 481 479 478 483 482 479 481 481 479 478 478 479 479 481 478
				481 482 481 482 483 482 478 480 482 484 482 482 482 482 481 478 484 480 479 478 478 478 479 480 479 481 481 481 478 478 482 481
				481 481 479 481 479 479 478 478 482 479 479 481 482 481 481 479 484 476 477 479 478 478 479 479 478 479 478 480 479 479 479 482
				481 480 478 479 480 482 478 479 478 481 480 478 479 477 479 481 480 478 478 479 479 479 479 480 481 482 482 481 479 479 479 482
				478 479 478 479 480 477 481 482 481 482 481 481 481 481 481 479 481 480 479 481 478 480 479 481 479 477 478 477 479 479 480 482
				478 481 483 482 481 482 483 477 481 484 482 482 481 480 481 482 481 481 480 481 481 481 481 480 483 484 484 482 482 481 480 481
				482 480 481 478 481 477 480 480 484 484 483 482 484 482 482 479 481 484 481 478 482 481 481 478 480 481 478 479 481 481 479 478
				482 480 479 480 478 479 479 481 481 482 480 479 481 482 480 481 478 483 481 481 481 479 479 481 484 481 482 483 478 476 482 476
				479 480 481 482 481 482 481 478 481 481 481 481 480 478 481 478 482 481 480 479 481 480 481 480 481 481 479 481 481 482 479 480
				481 479 481 481 482 482 478 481 479 480 481 479 478 478 478 478 477 483 482 483 484 485 478 481 478 478 479 481 481 479 481 481
				479 481 480 482 481 481 482 479 478 477 476 477 481 478 479 479 479 481 478 481 480 480 484 478 479 480 481 479 482 479 479 483
				482 479 479 480 478 480 479 483 482 481 481 482 482 481 481 482 479 479 478 481 481 482 477 482 481 479 478 478 481 480 481 485
				478 480 478 480 480 479 479 481 478 479 478 479 479 480 480 481 481 481 478 479 477 481 481 479 479 478 478 480 482 481 481 480
				479 481 479 481 477 480 480 478 480 484 484 480 479 479 479 482 481 482 479 480 479 478 480 481 480 480 480 480 481 482 484 482
				477 481 481 482 481 482 479 484 478 479 478 480 481 482 482 482 482 479 475 480 479 479 479 479 479 479 478 479 481 481 481 480
				240 240 240>;

			PS_Config_Lmt_FW_CC_P = <
				222	219	219	219	218	216	216	218	222	219	219	219	219	219	219	220	219	218	218	218	216	216	216	216	219	216	218	216	218	218	216	219
				222	220	220	219	218	218	219	219	216	215	215	215	215	215	216	219	222	220	219	219	219	218	218	218	218	216	216	216	216	216	216	218
				242	235	235	238	238	235	235	235	237	235	235	235	235	235	235	245	244	237	237	235	234	235	235	235	235	235	235	234	234	234	235	244
				233	231	231	231	231	231	229	230	233	231	231	231	231	231	231	233	234	230	233	231	229	229	229	229	231	229	229	229	230	229	230	231
				235	233	233	233	235	233	233	233	233	233	233	233	233	233	233	233	234	233	233	233	231	230	230	230	230	230	230	229	229	230	230	231
				238	235	235	235	235	233	233	233	237	234	234	234	234	234	235	235	235	234	234	234	233	231	231	231	235	235	231	231	231	234	235	235
				235	234	234	234	233	233	231	233	235	233	231	233	231	235	235	235	237	235	235	235	233	233	231	233	233	233	233	233	233	233	233	234
				233	230	230	230	231	231	231	231	234	233	231	233	234	234	234	233	233	231	231	230	230	229	229	229	233	231	231	231	231	231	231	233
				235	234	234	234	233	231	233	233	234	235	235	235	235	234	237	237	234	234	234	234	233	233	233	233	234	234	233	234	234	235	234	237
				235	234	234	234	234	234	234	234	230	231	230	231	231	231	231	235	235	235	234	234	234	233	233	233	229	230	229	230	230	230	233	231
				235	234	234	233	233	231	231	233	235	235	234	235	235	237	237	237	231	230	229	230	230	230	230	230	231	231	233	231	231	231	233	235
				235	234	234	234	233	233	233	234	233	233	233	233	233	233	234	234	234	234	234	234	233	233	233	233	233	233	233	233	233	233	233	235
				233	231	231	231	231	231	231	231	233	233	233	233	233	233	235	235	233	230	230	230	231	229	227	230	233	233	234	234	234	234	233	234
				237	233	235	233	233	233	235	235	233	230	233	233	230	230	230	234	235	234	233	233	233	233	233	233	233	233	230	233	233	233	233	234
				237	237	237	237	235	235	237	237	237	240	235	235	240	237	240	237	237	235	235	237	235	235	233	235	234	234	234	234	234	234	234	237
				234	233	233	233	233	233	233	234	234	234	233	234	234	234	235	234	233	229	229	229	229	229	229	230	230	230	230	230	230	230	233	233
				235	234	234	234	234	233	233	234	233	233	233	233	233	233	235	234	234	234	234	234	234	231	231	231	231	233	231	233	233	233	233	233
				235	234	234	234	234	234	235	235	238	238	238	237	237	238	238	238	237	235	235	235	235	235	235	235	235	234	234	234	234	234	234	237
				237	235	235	235	234	235	235	235	235	235	235	235	235	235	235	238	235	234	234	234	233	234	234	234	234	235	235	233	233	234	234	235
				233	233	230	230	231	231	233	233	233	235	231	231	231	231	235	235	231	231	230	231	230	230	230	230	233	233	233	233	233	233	233	235
				235	234	234	234	234	234	237	237	234	235	234	235	235	234	235	237	235	235	235	235	234	235	235	235	235	235	233	233	233	233	235	235
				237	235	235	235	235	235	238	235	237	237	237	237	237	237	237	237	237	235	235	235	235	234	234	234	234	234	234	235	235	235	235	237
				234	234	234	234	234	234	234	234	235	235	235	235	235	235	235	237	235	235	235	234	234	234	234	234	235	235	234	234	235	234	234	235
				238	237	237	233	237	237	234	237	234	234	235	234	235	234	234	234	234	237	237	233	237	237	237	237	233	233	233	233	233	233	233	234
				235	234	234	234	234	231	233	231	233	233	233	233	233	233	233	240	231	231	231	230	230	230	231	231	234	234	231	234	231	231	234	237
				240	234	234	235	234	234	234	234	235	238	235	235	234	235	235	238	238	234	233	231	233	233	233	233	233	233	233	233	231	235	234	234
				240	238	238	238	238	238	237	237	237	237	240	240	240	240	240	237	240	238	238	238	238	238	238	238	237	235	235	237	235	235	235	237
				234	231	231	231	233	233	233	233	234	234	235	234	235	234	234	234	233	231	231	231	231	231	230	230	233	235	231	231	231	231	231	235
				237	235	235	235	235	235	235	235	233	233	234	235	234	233	234	233	237	235	235	235	235	235	235	235	233	231	233	233	233	233	233	234
				240	235	235	235	235	235	235	235	237	240	240	240	238	238	240	237	238	237	237	237	237	237	237	237	234	234	234	234	237	237	237	237
				237	234	234	234	234	234	234	237	238	235	235	234	234	234	238	238	237	237	235	234	234	235	235	235	235	235	235	235	231	234	234	233
				235	235	233	233	233	235	235	235	235	235	235	235	235	235	235	235	234	235	235	233	233	231	231	231	233	233	233	233	233	233	233	235
				237	235	233	233	233	235	233	233	237	237	237	237	237	237	237	238	234	234	234	234	234	234	234	234	234	234	234	233	233	233	233	234
				238	235	235	235	235	235	235	235	234	234	235	235	235	235	235	235	238	237	234	234	234	234	235	235	233	233	233	231	231	231	231	235
				238	237	237	237	237	237	235	235	237	237	237	237	237	237	237	235	235	235	235	235	235	235	235	235	235	234	234	234	234	234	234	235
				238	235	235	235	235	235	237	237	234	234	234	234	234	234	234	235	237	237	237	237	235	235	237	237	235	234	234	234	234	235	235	235
				234	231	231	231	231	231	231	231	233	234	234	234	233	233	234	235	233	234	234	234	234	233	233	233	231	231	230	230	230	233	233	234
				235	235	234	235	235	235	234	234	234	235	235	235	234	234	234	237	235	235	235	235	235	235	235	235	233	233	233	233	233	233	235	235
				237	238	237	237	237	237	238	238	237	237	237	237	237	238	238	238	238	240	238	235	235	235	235	235	234	234	234	234	234	234	234	237
				234	233	233	233	233	233	233	234	235	235	235	235	235	235	233	235	231	234	231	231	231	230	231	231	233	233	233	233	233	233	233	235
				237	235	235	235	234	235	235	235	234	233	233	233	233	234	234	235	234	234	234	234	234	234	234	235	233	233	233	233	233	233	234	235
				240	238	238	238	238	238	237	237	238	238	240	240	240	240	240	241	237	235	235	235	235	237	237	235	238	238	238	238	238	238	238	240
				237	237	237	237	237	237	235	237	235	235	235	235	235	235	235	237	234	233	234	234	234	234	235	235	233	233	234	233	233	233	234	235
				235	235	235	235	235	235	235	235	234	235	235	234	234	234	234	235	234	231	231	231	233	233	233	234	233	233	233	235	235	235	235	237
				237	237	237	237	237	237	235	237	235	237	237	235	235	235	235	235	237	235	235	235	235	235	237	238	234	234	234	234	234	234	234	237
				237	235	235	234	235	235	235	237	237	237	237	237	237	237	237	238	235	234	234	234	234	234	237	235	234	234	234	235	235	234	234	237
				235	235	235	233	235	233	235	235	235	233	235	235	237	237	237	238	234	233	233	233	231	233	234	234	233	233	233	233	235	235	234	237
				244	237	237	235	237	237	237	238	235	235	235	234	234	234	234	241	241	237	235	235	235	235	237	238	233	233	233	234	234	234	234	242
				233	233	230	230	230	230	233	233	234	233	233	234	234	235	235	235	230	230	233	230	230	230	230	233	233	233	233	233	234	234	234	235
				233	231	230	231	231	231	230	237	230	230	230	231	230	233	233	242	231	231	229	229	229	231	231	235	231	231	231	231	230	234	234	237
				314 314 314>;

			PS_Config_Lmt_FW_CC_N = <
				99	98	98	98	97	97	97	97	99	98	98	98	98	98	98	99	98	97	97	97	97	97	97	97	98	97	97	97	97	97	97	98
				99	99	99	98	97	97	98	98	97	96	96	96	96	96	97	98	99	99	98	98	98	97	97	97	97	97	97	97	97	97	97	97
				109	106	106	107	107	106	106	106	106	106	106	106	106	106	106	110	109	106	106	106	105	106	106	106	106	106	106	105	105	105	106	109
				104	104	104	104	104	104	102	103	104	104	104	104	104	104	104	104	105	103	104	104	102	102	102	102	104	102	102	102	103	102	103	104
				106	104	104	104	106	104	104	104	104	104	104	104	104	104	104	104	105	104	104	104	104	103	103	103	103	103	103	102	102	103	103	104
				107	106	106	106	106	104	104	104	106	105	105	105	105	105	106	106	106	105	105	105	104	104	104	104	106	106	104	104	104	105	106	106
				106	105	105	105	104	104	104	104	106	104	104	104	104	106	106	106	106	106	106	106	104	104	104	104	104	104	104	104	104	104	104	105
				104	103	103	103	104	104	104	104	105	104	104	104	105	105	105	104	104	104	104	103	103	102	102	102	104	104	104	104	104	104	104	104
				106	105	105	105	104	104	104	104	105	106	106	106	106	105	106	106	105	105	105	105	104	104	104	104	105	105	104	105	105	106	105	106
				106	105	105	105	105	105	105	105	103	104	103	104	104	104	104	106	106	106	105	105	105	104	104	104	102	103	102	103	103	103	104	104
				106	105	105	104	104	104	104	104	106	106	105	106	106	106	106	106	104	103	102	103	103	103	103	103	104	104	104	104	104	104	104	106
				106	105	105	105	104	104	104	105	104	104	104	104	104	104	105	105	105	105	105	105	104	104	104	104	104	104	104	104	104	104	104	106
				104	104	104	104	104	104	104	104	104	104	104	104	104	104	106	106	104	103	103	103	104	102	102	103	104	104	105	105	105	105	104	105
				106	104	106	104	104	104	106	106	104	103	104	104	103	103	103	105	106	105	104	104	104	104	104	104	104	104	103	104	104	104	104	105
				106	106	106	106	106	106	106	106	106	107	106	106	107	106	107	106	106	106	106	106	106	106	104	106	105	105	105	105	105	105	105	106
				105	104	104	104	104	104	104	105	105	105	104	105	105	105	106	105	104	102	102	102	102	102	102	103	103	103	103	103	103	103	104	104
				106	105	105	105	105	104	104	105	104	104	104	104	104	104	106	105	105	105	105	105	105	104	104	104	104	104	104	104	104	104	104	104
				106	105	105	105	105	105	106	106	107	107	107	106	106	107	107	107	106	106	106	106	106	106	106	106	106	105	105	105	105	105	105	106
				106	106	106	106	105	106	106	106	106	106	106	106	106	106	106	107	106	105	105	105	104	105	105	105	105	106	106	104	104	105	105	106
				104	104	103	103	104	104	104	104	104	106	104	104	104	104	106	106	104	104	103	104	103	103	103	103	104	104	104	104	104	104	104	106
				106	105	105	105	105	105	106	106	105	106	105	106	106	105	106	106	106	106	106	106	105	106	106	106	106	106	104	104	104	104	106	106
				106	106	106	106	106	106	107	106	106	106	106	106	106	106	106	106	106	106	106	106	106	105	105	105	105	105	105	106	106	106	106	106
				105	105	105	105	105	105	105	105	106	106	106	106	106	106	106	106	106	106	106	105	105	105	105	105	106	106	105	105	106	105	105	106
				107	106	106	104	106	106	105	106	105	105	106	105	106	105	105	105	105	106	106	104	106	106	106	106	104	104	104	104	104	104	104	105
				106	105	105	105	105	104	104	104	104	104	104	104	104	104	104	107	104	104	104	103	103	103	104	104	105	105	104	105	104	104	105	106
				107	105	105	106	105	105	105	105	106	107	106	106	105	106	106	107	107	105	104	104	104	104	104	104	104	104	104	104	104	106	105	105
				107	107	107	107	107	107	106	106	106	106	107	107	107	107	107	106	107	107	107	107	107	107	107	107	106	106	106	106	106	106	106	106
				105	104	104	104	104	104	104	104	105	105	106	105	106	105	105	105	104	104	104	104	104	104	103	103	104	106	104	104	104	104	104	106
				106	106	106	106	106	106	106	106	104	104	105	106	105	104	105	104	106	106	106	106	106	106	106	106	104	104	104	104	104	104	104	105
				107	106	106	106	106	106	106	106	106	107	107	107	107	107	107	106	107	106	106	106	106	106	106	106	105	105	105	105	106	106	106	106
				106	105	105	105	105	105	105	106	107	106	106	105	105	105	107	107	106	106	106	105	105	106	106	106	106	106	106	106	104	105	105	104
				106	106	104	104	104	106	106	106	106	106	106	106	106	106	106	106	105	106	106	104	104	104	104	104	104	104	104	104	104	104	104	106
				106	106	104	104	104	106	104	104	106	106	106	106	106	106	106	107	105	105	105	105	105	105	105	105	105	105	105	104	104	104	104	105
				107	106	106	106	106	106	106	106	105	105	106	106	106	106	106	106	107	106	105	105	105	105	106	106	104	104	104	104	104	104	104	106
				107	106	106	106	106	106	106	106	106	106	106	106	106	106	106	106	106	106	106	106	106	106	106	106	106	105	105	105	105	105	105	106
				107	106	106	106	106	106	106	106	105	105	105	105	105	105	105	106	106	106	106	106	106	106	106	106	106	105	105	105	105	106	106	106
				105	104	104	104	104	104	104	104	104	105	105	105	104	104	105	106	104	105	105	105	105	104	104	104	104	104	103	103	103	104	104	105
				106	106	105	106	106	106	105	105	105	106	106	106	105	105	105	106	106	106	106	106	106	106	106	106	104	104	104	104	104	104	106	106
				106	107	106	106	106	106	107	107	106	106	106	106	106	107	107	107	107	107	107	106	106	106	106	106	105	105	105	105	105	105	105	106
				105	104	104	104	104	104	104	105	106	106	106	106	106	106	104	106	104	105	104	104	104	103	104	104	104	104	104	104	104	104	104	106
				106	106	106	106	105	106	106	106	105	104	104	104	104	105	105	106	105	105	105	105	105	105	105	106	104	104	104	104	104	104	105	106
				107	107	107	107	107	107	106	106	107	107	107	107	107	107	107	108	106	106	106	106	106	106	106	106	107	107	107	107	107	107	107	107
				106	106	106	106	106	106	106	106	106	106	106	106	106	106	106	106	105	104	105	105	105	105	106	106	104	104	105	104	104	104	105	106
				106	106	106	106	106	106	106	106	105	106	106	105	105	105	105	106	105	104	104	104	104	104	104	105	104	104	104	106	106	106	106	106
				106	106	106	106	106	106	106	106	106	106	106	106	106	106	106	106	106	106	106	106	106	106	106	107	105	105	105	105	105	105	105	106
				106	106	106	105	106	106	106	106	106	106	106	106	106	106	106	107	106	105	105	105	105	105	106	106	105	105	105	106	106	105	105	106
				106	106	106	104	106	104	106	106	106	104	106	106	106	106	106	107	105	104	104	104	104	104	105	105	104	104	104	104	106	106	105	106
				109	106	106	106	106	106	106	107	106	106	106	105	105	105	105	108	108	106	106	106	106	106	106	107	104	104	104	105	105	105	105	109
				104	104	103	103	103	103	104	104	105	104	104	105	105	106	106	106	103	103	104	103	103	103	103	104	104	104	104	104	105	105	105	106
				104	104	103	104	104	104	103	106	103	103	103	104	103	104	104	109	104	104	102	102	102	104	104	106	104	104	104	104	103	105	105	106
				0 0 0>;

			PS_Config_Lmt_FW_Diff_P = <
				90 90 90 90 90 90 90 90 90 90 90 90 90 90 90 90 90 90 90 90 90 90 90 90 90 90 90 90 90 90 90 90
				90 90 90 90 90 90 90 90 90 90 90 90 90 90 90 90 90 90 90 90 90 90 90 90 90 90 90 90 90 90 90 90
				90 90 90 90 90 90 90 90 90 90 90 90 90 90 90 90 90 90 90 90 90 90 90 90 90 90 90 90 90 90 90 90
				90 90 90 90 90 90 90 90 90 90 90 90 90 90 90 90 90 90 90 90 90 90 90 90 90 90 90 90 90 90 90 90
				90 90 90 90 90 90 90 90 90 90 90 90 90 90 90 90 90 90 90 90 90 90 90 90 90 90 90 90 90 90 90 90
				90 90 90 90 90 90 90 90 90 90 90 90 90 90 90 90 90 90 90 90 90 90 90 90 90 90 90 90 90 90 90 90
				90 90 90 90 90 90 90 90 90 90 90 90 90 90 90 90 90 90 90 90 90 90 90 90 90 90 90 90 90 90 90 90
				90 90 90 90 90 90 90 90 90 90 90 90 90 90 90 90 90 90 90 90 90 90 90 90 90 90 90 90 90 90 90 90
				90 90 90 90 90 90 90 90 90 90 90 90 90 90 90 90 90 90 90 90 90 90 90 90 90 90 90 90 90 90 90 90
				90 90 90 90 90 90 90 90 90 90 90 90 90 90 90 90 90 90 90 90 90 90 90 90 90 90 90 90 90 90 90 90
				90 90 90 90 90 90 90 90 90 90 90 90 90 90 90 90 90 90 90 90 90 90 90 90 90 90 90 90 90 90 90 90
				90 90 90 90 90 90 90 90 90 90 90 90 90 90 90 90 90 90 90 90 90 90 90 90 90 90 90 90 90 90 90 90
				90 90 90 90 90 90 90 90 90 90 90 90 90 90 90 90 90 90 90 90 90 90 90 90 90 90 90 90 90 90 90 90
				90 90 90 90 90 90 90 90 90 90 90 90 90 90 90 90 90 90 90 90 90 90 90 90 90 90 90 90 90 90 90 90
				90 90 90 90 90 90 90 90 90 90 90 90 90 90 90 90 90 90 90 90 90 90 90 90 90 90 90 90 90 90 90 90
				90 90 90 90 90 90 90 90 90 90 90 90 90 90 90 90 90 90 90 90 90 90 90 90 90 90 90 90 90 90 90 90
				90 90 90 90 90 90 90 90 90 90 90 90 90 90 90 90 90 90 90 90 90 90 90 90 90 90 90 90 90 90 90 90
				90 90 90 90 90 90 90 90 90 90 90 90 90 90 90 90 90 90 90 90 90 90 90 90 90 90 90 90 90 90 90 90
				90 90 90 90 90 90 90 90 90 90 90 90 90 90 90 90 90 90 90 90 90 90 90 90 90 90 90 90 90 90 90 90
				90 90 90 90 90 90 90 90 90 90 90 90 90 90 90 90 90 90 90 90 90 90 90 90 90 90 90 90 90 90 90 90
				90 90 90 90 90 90 90 90 90 90 90 90 90 90 90 90 90 90 90 90 90 90 90 90 90 90 90 90 90 90 90 90
				90 90 90 90 90 90 90 90 90 90 90 90 90 90 90 90 90 90 90 90 90 90 90 90 90 90 90 90 90 90 90 90
				90 90 90 90 90 90 90 90 90 90 90 90 90 90 90 90 90 90 90 90 90 90 90 90 90 90 90 90 90 90 90 90
				90 90 90 90 90 90 90 90 90 90 90 90 90 90 90 90 90 90 90 90 90 90 90 90 90 90 90 90 90 90 90 90
				90 90 90 90 90 90 90 90 90 90 90 90 90 90 90 90 90 90 90 90 90 90 90 90 90 90 90 90 90 90 90 90
				90 90 90 90 90 90 90 90 90 90 90 90 90 90 90 90 90 90 90 90 90 90 90 90 90 90 90 90 90 90 90 90
				90 90 90 90 90 90 90 90 90 90 90 90 90 90 90 90 90 90 90 90 90 90 90 90 90 90 90 90 90 90 90 90
				90 90 90 90 90 90 90 90 90 90 90 90 90 90 90 90 90 90 90 90 90 90 90 90 90 90 90 90 90 90 90 90
				90 90 90 90 90 90 90 90 90 90 90 90 90 90 90 90 90 90 90 90 90 90 90 90 90 90 90 90 90 90 90 90
				90 90 90 90 90 90 90 90 90 90 90 90 90 90 90 90 90 90 90 90 90 90 90 90 90 90 90 90 90 90 90 90
				90 90 90 90 90 90 90 90 90 90 90 90 90 90 90 90 90 90 90 90 90 90 90 90 90 90 90 90 90 90 90 90
				90 90 90 90 90 90 90 90 90 90 90 90 90 90 90 90 90 90 90 90 90 90 90 90 90 90 90 90 90 90 90 90
				90 90 90 90 90 90 90 90 90 90 90 90 90 90 90 90 90 90 90 90 90 90 90 90 90 90 90 90 90 90 90 90
				90 90 90 90 90 90 90 90 90 90 90 90 90 90 90 90 90 90 90 90 90 90 90 90 90 90 90 90 90 90 90 90
				90 90 90 90 90 90 90 90 90 90 90 90 90 90 90 90 90 90 90 90 90 90 90 90 90 90 90 90 90 90 90 90
				90 90 90 90 90 90 90 90 90 90 90 90 90 90 90 90 90 90 90 90 90 90 90 90 90 90 90 90 90 90 90 90
				90 90 90 90 90 90 90 90 90 90 90 90 90 90 90 90 90 90 90 90 90 90 90 90 90 90 90 90 90 90 90 90
				90 90 90 90 90 90 90 90 90 90 90 90 90 90 90 90 90 90 90 90 90 90 90 90 90 90 90 90 90 90 90 90
				90 90 90 90 90 90 90 90 90 90 90 90 90 90 90 90 90 90 90 90 90 90 90 90 90 90 90 90 90 90 90 90
				90 90 90 90 90 90 90 90 90 90 90 90 90 90 90 90 90 90 90 90 90 90 90 90 90 90 90 90 90 90 90 90
				90 90 90 90 90 90 90 90 90 90 90 90 90 90 90 90 90 90 90 90 90 90 90 90 90 90 90 90 90 90 90 90
				90 90 90 90 90 90 90 90 90 90 90 90 90 90 90 90 90 90 90 90 90 90 90 90 90 90 90 90 90 90 90 90
				90 90 90 90 90 90 90 90 90 90 90 90 90 90 90 90 90 90 90 90 90 90 90 90 90 90 90 90 90 90 90 90
				90 90 90 90 90 90 90 90 90 90 90 90 90 90 90 90 90 90 90 90 90 90 90 90 90 90 90 90 90 90 90 90
				90 90 90 90 90 90 90 90 90 90 90 90 90 90 90 90 90 90 90 90 90 90 90 90 90 90 90 90 90 90 90 90
				90 90 90 90 90 90 90 90 90 90 90 90 90 90 90 90 90 90 90 90 90 90 90 90 90 90 90 90 90 90 90 90
				90 90 90 90 90 90 90 90 90 90 90 90 90 90 90 90 90 90 90 90 90 90 90 90 90 90 90 90 90 90 90 90
				90 90 90 90 90 90 90 90 90 90 90 90 90 90 90 90 90 90 90 90 90 90 90 90 90 90 90 90 90 90 90 90
				90 90 90 90 90 90 90 90 90 90 90 90 90 90 90 90 90 90 90 90 90 90 90 90 90 90 90 90 90 90 90 90
				90 90 90 90 90 90 90 90 90 90 90 90 90 90 90 90 90 90 90 90 90 90 90 90 90 90 90 90 90 90 90 90
				90 90 90>;

			PS_Config_Lmt_FW_Diff_N = <
				(-90) (-90) (-90) (-90) (-90) (-90) (-90) (-90) (-90) (-90) (-90) (-90) (-90) (-90) (-90) (-90) (-90) (-90) (-90) (-90) (-90) (-90) (-90) (-90) (-90) (-90) (-90) (-90) (-90) (-90) (-90) (-90)
				(-90) (-90) (-90) (-90) (-90) (-90) (-90) (-90) (-90) (-90) (-90) (-90) (-90) (-90) (-90) (-90) (-90) (-90) (-90) (-90) (-90) (-90) (-90) (-90) (-90) (-90) (-90) (-90) (-90) (-90) (-90) (-90)
				(-90) (-90) (-90) (-90) (-90) (-90) (-90) (-90) (-90) (-90) (-90) (-90) (-90) (-90) (-90) (-90) (-90) (-90) (-90) (-90) (-90) (-90) (-90) (-90) (-90) (-90) (-90) (-90) (-90) (-90) (-90) (-90)
				(-90) (-90) (-90) (-90) (-90) (-90) (-90) (-90) (-90) (-90) (-90) (-90) (-90) (-90) (-90) (-90) (-90) (-90) (-90) (-90) (-90) (-90) (-90) (-90) (-90) (-90) (-90) (-90) (-90) (-90) (-90) (-90)
				(-90) (-90) (-90) (-90) (-90) (-90) (-90) (-90) (-90) (-90) (-90) (-90) (-90) (-90) (-90) (-90) (-90) (-90) (-90) (-90) (-90) (-90) (-90) (-90) (-90) (-90) (-90) (-90) (-90) (-90) (-90) (-90)
				(-90) (-90) (-90) (-90) (-90) (-90) (-90) (-90) (-90) (-90) (-90) (-90) (-90) (-90) (-90) (-90) (-90) (-90) (-90) (-90) (-90) (-90) (-90) (-90) (-90) (-90) (-90) (-90) (-90) (-90) (-90) (-90)
				(-90) (-90) (-90) (-90) (-90) (-90) (-90) (-90) (-90) (-90) (-90) (-90) (-90) (-90) (-90) (-90) (-90) (-90) (-90) (-90) (-90) (-90) (-90) (-90) (-90) (-90) (-90) (-90) (-90) (-90) (-90) (-90)
				(-90) (-90) (-90) (-90) (-90) (-90) (-90) (-90) (-90) (-90) (-90) (-90) (-90) (-90) (-90) (-90) (-90) (-90) (-90) (-90) (-90) (-90) (-90) (-90) (-90) (-90) (-90) (-90) (-90) (-90) (-90) (-90)
				(-90) (-90) (-90) (-90) (-90) (-90) (-90) (-90) (-90) (-90) (-90) (-90) (-90) (-90) (-90) (-90) (-90) (-90) (-90) (-90) (-90) (-90) (-90) (-90) (-90) (-90) (-90) (-90) (-90) (-90) (-90) (-90)
				(-90) (-90) (-90) (-90) (-90) (-90) (-90) (-90) (-90) (-90) (-90) (-90) (-90) (-90) (-90) (-90) (-90) (-90) (-90) (-90) (-90) (-90) (-90) (-90) (-90) (-90) (-90) (-90) (-90) (-90) (-90) (-90)
				(-90) (-90) (-90) (-90) (-90) (-90) (-90) (-90) (-90) (-90) (-90) (-90) (-90) (-90) (-90) (-90) (-90) (-90) (-90) (-90) (-90) (-90) (-90) (-90) (-90) (-90) (-90) (-90) (-90) (-90) (-90) (-90)
				(-90) (-90) (-90) (-90) (-90) (-90) (-90) (-90) (-90) (-90) (-90) (-90) (-90) (-90) (-90) (-90) (-90) (-90) (-90) (-90) (-90) (-90) (-90) (-90) (-90) (-90) (-90) (-90) (-90) (-90) (-90) (-90)
				(-90) (-90) (-90) (-90) (-90) (-90) (-90) (-90) (-90) (-90) (-90) (-90) (-90) (-90) (-90) (-90) (-90) (-90) (-90) (-90) (-90) (-90) (-90) (-90) (-90) (-90) (-90) (-90) (-90) (-90) (-90) (-90)
				(-90) (-90) (-90) (-90) (-90) (-90) (-90) (-90) (-90) (-90) (-90) (-90) (-90) (-90) (-90) (-90) (-90) (-90) (-90) (-90) (-90) (-90) (-90) (-90) (-90) (-90) (-90) (-90) (-90) (-90) (-90) (-90)
				(-90) (-90) (-90) (-90) (-90) (-90) (-90) (-90) (-90) (-90) (-90) (-90) (-90) (-90) (-90) (-90) (-90) (-90) (-90) (-90) (-90) (-90) (-90) (-90) (-90) (-90) (-90) (-90) (-90) (-90) (-90) (-90)
				(-90) (-90) (-90) (-90) (-90) (-90) (-90) (-90) (-90) (-90) (-90) (-90) (-90) (-90) (-90) (-90) (-90) (-90) (-90) (-90) (-90) (-90) (-90) (-90) (-90) (-90) (-90) (-90) (-90) (-90) (-90) (-90)
				(-90) (-90) (-90) (-90) (-90) (-90) (-90) (-90) (-90) (-90) (-90) (-90) (-90) (-90) (-90) (-90) (-90) (-90) (-90) (-90) (-90) (-90) (-90) (-90) (-90) (-90) (-90) (-90) (-90) (-90) (-90) (-90)
				(-90) (-90) (-90) (-90) (-90) (-90) (-90) (-90) (-90) (-90) (-90) (-90) (-90) (-90) (-90) (-90) (-90) (-90) (-90) (-90) (-90) (-90) (-90) (-90) (-90) (-90) (-90) (-90) (-90) (-90) (-90) (-90)
				(-90) (-90) (-90) (-90) (-90) (-90) (-90) (-90) (-90) (-90) (-90) (-90) (-90) (-90) (-90) (-90) (-90) (-90) (-90) (-90) (-90) (-90) (-90) (-90) (-90) (-90) (-90) (-90) (-90) (-90) (-90) (-90)
				(-90) (-90) (-90) (-90) (-90) (-90) (-90) (-90) (-90) (-90) (-90) (-90) (-90) (-90) (-90) (-90) (-90) (-90) (-90) (-90) (-90) (-90) (-90) (-90) (-90) (-90) (-90) (-90) (-90) (-90) (-90) (-90)
				(-90) (-90) (-90) (-90) (-90) (-90) (-90) (-90) (-90) (-90) (-90) (-90) (-90) (-90) (-90) (-90) (-90) (-90) (-90) (-90) (-90) (-90) (-90) (-90) (-90) (-90) (-90) (-90) (-90) (-90) (-90) (-90)
				(-90) (-90) (-90) (-90) (-90) (-90) (-90) (-90) (-90) (-90) (-90) (-90) (-90) (-90) (-90) (-90) (-90) (-90) (-90) (-90) (-90) (-90) (-90) (-90) (-90) (-90) (-90) (-90) (-90) (-90) (-90) (-90)
				(-90) (-90) (-90) (-90) (-90) (-90) (-90) (-90) (-90) (-90) (-90) (-90) (-90) (-90) (-90) (-90) (-90) (-90) (-90) (-90) (-90) (-90) (-90) (-90) (-90) (-90) (-90) (-90) (-90) (-90) (-90) (-90)
				(-90) (-90) (-90) (-90) (-90) (-90) (-90) (-90) (-90) (-90) (-90) (-90) (-90) (-90) (-90) (-90) (-90) (-90) (-90) (-90) (-90) (-90) (-90) (-90) (-90) (-90) (-90) (-90) (-90) (-90) (-90) (-90)
				(-90) (-90) (-90) (-90) (-90) (-90) (-90) (-90) (-90) (-90) (-90) (-90) (-90) (-90) (-90) (-90) (-90) (-90) (-90) (-90) (-90) (-90) (-90) (-90) (-90) (-90) (-90) (-90) (-90) (-90) (-90) (-90)
				(-90) (-90) (-90) (-90) (-90) (-90) (-90) (-90) (-90) (-90) (-90) (-90) (-90) (-90) (-90) (-90) (-90) (-90) (-90) (-90) (-90) (-90) (-90) (-90) (-90) (-90) (-90) (-90) (-90) (-90) (-90) (-90)
				(-90) (-90) (-90) (-90) (-90) (-90) (-90) (-90) (-90) (-90) (-90) (-90) (-90) (-90) (-90) (-90) (-90) (-90) (-90) (-90) (-90) (-90) (-90) (-90) (-90) (-90) (-90) (-90) (-90) (-90) (-90) (-90)
				(-90) (-90) (-90) (-90) (-90) (-90) (-90) (-90) (-90) (-90) (-90) (-90) (-90) (-90) (-90) (-90) (-90) (-90) (-90) (-90) (-90) (-90) (-90) (-90) (-90) (-90) (-90) (-90) (-90) (-90) (-90) (-90)
				(-90) (-90) (-90) (-90) (-90) (-90) (-90) (-90) (-90) (-90) (-90) (-90) (-90) (-90) (-90) (-90) (-90) (-90) (-90) (-90) (-90) (-90) (-90) (-90) (-90) (-90) (-90) (-90) (-90) (-90) (-90) (-90)
				(-90) (-90) (-90) (-90) (-90) (-90) (-90) (-90) (-90) (-90) (-90) (-90) (-90) (-90) (-90) (-90) (-90) (-90) (-90) (-90) (-90) (-90) (-90) (-90) (-90) (-90) (-90) (-90) (-90) (-90) (-90) (-90)
				(-90) (-90) (-90) (-90) (-90) (-90) (-90) (-90) (-90) (-90) (-90) (-90) (-90) (-90) (-90) (-90) (-90) (-90) (-90) (-90) (-90) (-90) (-90) (-90) (-90) (-90) (-90) (-90) (-90) (-90) (-90) (-90)
				(-90) (-90) (-90) (-90) (-90) (-90) (-90) (-90) (-90) (-90) (-90) (-90) (-90) (-90) (-90) (-90) (-90) (-90) (-90) (-90) (-90) (-90) (-90) (-90) (-90) (-90) (-90) (-90) (-90) (-90) (-90) (-90)
				(-90) (-90) (-90) (-90) (-90) (-90) (-90) (-90) (-90) (-90) (-90) (-90) (-90) (-90) (-90) (-90) (-90) (-90) (-90) (-90) (-90) (-90) (-90) (-90) (-90) (-90) (-90) (-90) (-90) (-90) (-90) (-90)
				(-90) (-90) (-90) (-90) (-90) (-90) (-90) (-90) (-90) (-90) (-90) (-90) (-90) (-90) (-90) (-90) (-90) (-90) (-90) (-90) (-90) (-90) (-90) (-90) (-90) (-90) (-90) (-90) (-90) (-90) (-90) (-90)
				(-90) (-90) (-90) (-90) (-90) (-90) (-90) (-90) (-90) (-90) (-90) (-90) (-90) (-90) (-90) (-90) (-90) (-90) (-90) (-90) (-90) (-90) (-90) (-90) (-90) (-90) (-90) (-90) (-90) (-90) (-90) (-90)
				(-90) (-90) (-90) (-90) (-90) (-90) (-90) (-90) (-90) (-90) (-90) (-90) (-90) (-90) (-90) (-90) (-90) (-90) (-90) (-90) (-90) (-90) (-90) (-90) (-90) (-90) (-90) (-90) (-90) (-90) (-90) (-90)
				(-90) (-90) (-90) (-90) (-90) (-90) (-90) (-90) (-90) (-90) (-90) (-90) (-90) (-90) (-90) (-90) (-90) (-90) (-90) (-90) (-90) (-90) (-90) (-90) (-90) (-90) (-90) (-90) (-90) (-90) (-90) (-90)
				(-90) (-90) (-90) (-90) (-90) (-90) (-90) (-90) (-90) (-90) (-90) (-90) (-90) (-90) (-90) (-90) (-90) (-90) (-90) (-90) (-90) (-90) (-90) (-90) (-90) (-90) (-90) (-90) (-90) (-90) (-90) (-90)
				(-90) (-90) (-90) (-90) (-90) (-90) (-90) (-90) (-90) (-90) (-90) (-90) (-90) (-90) (-90) (-90) (-90) (-90) (-90) (-90) (-90) (-90) (-90) (-90) (-90) (-90) (-90) (-90) (-90) (-90) (-90) (-90)
				(-90) (-90) (-90) (-90) (-90) (-90) (-90) (-90) (-90) (-90) (-90) (-90) (-90) (-90) (-90) (-90) (-90) (-90) (-90) (-90) (-90) (-90) (-90) (-90) (-90) (-90) (-90) (-90) (-90) (-90) (-90) (-90)
				(-90) (-90) (-90) (-90) (-90) (-90) (-90) (-90) (-90) (-90) (-90) (-90) (-90) (-90) (-90) (-90) (-90) (-90) (-90) (-90) (-90) (-90) (-90) (-90) (-90) (-90) (-90) (-90) (-90) (-90) (-90) (-90)
				(-90) (-90) (-90) (-90) (-90) (-90) (-90) (-90) (-90) (-90) (-90) (-90) (-90) (-90) (-90) (-90) (-90) (-90) (-90) (-90) (-90) (-90) (-90) (-90) (-90) (-90) (-90) (-90) (-90) (-90) (-90) (-90)
				(-90) (-90) (-90) (-90) (-90) (-90) (-90) (-90) (-90) (-90) (-90) (-90) (-90) (-90) (-90) (-90) (-90) (-90) (-90) (-90) (-90) (-90) (-90) (-90) (-90) (-90) (-90) (-90) (-90) (-90) (-90) (-90)
				(-90) (-90) (-90) (-90) (-90) (-90) (-90) (-90) (-90) (-90) (-90) (-90) (-90) (-90) (-90) (-90) (-90) (-90) (-90) (-90) (-90) (-90) (-90) (-90) (-90) (-90) (-90) (-90) (-90) (-90) (-90) (-90)
				(-90) (-90) (-90) (-90) (-90) (-90) (-90) (-90) (-90) (-90) (-90) (-90) (-90) (-90) (-90) (-90) (-90) (-90) (-90) (-90) (-90) (-90) (-90) (-90) (-90) (-90) (-90) (-90) (-90) (-90) (-90) (-90)
				(-90) (-90) (-90) (-90) (-90) (-90) (-90) (-90) (-90) (-90) (-90) (-90) (-90) (-90) (-90) (-90) (-90) (-90) (-90) (-90) (-90) (-90) (-90) (-90) (-90) (-90) (-90) (-90) (-90) (-90) (-90) (-90)
				(-90) (-90) (-90) (-90) (-90) (-90) (-90) (-90) (-90) (-90) (-90) (-90) (-90) (-90) (-90) (-90) (-90) (-90) (-90) (-90) (-90) (-90) (-90) (-90) (-90) (-90) (-90) (-90) (-90) (-90) (-90) (-90)
				(-90) (-90) (-90) (-90) (-90) (-90) (-90) (-90) (-90) (-90) (-90) (-90) (-90) (-90) (-90) (-90) (-90) (-90) (-90) (-90) (-90) (-90) (-90) (-90) (-90) (-90) (-90) (-90) (-90) (-90) (-90) (-90)
				(-90) (-90) (-90) (-90) (-90) (-90) (-90) (-90) (-90) (-90) (-90) (-90) (-90) (-90) (-90) (-90) (-90) (-90) (-90) (-90) (-90) (-90) (-90) (-90) (-90) (-90) (-90) (-90) (-90) (-90) (-90) (-90)
				(-90) (-90) (-90) (-90) (-90) (-90) (-90) (-90) (-90) (-90) (-90) (-90) (-90) (-90) (-90) (-90) (-90) (-90) (-90) (-90) (-90) (-90) (-90) (-90) (-90) (-90) (-90) (-90) (-90) (-90) (-90) (-90)
				(-90) (-90) (-90)>;

			PS_Config_Diff_Test_Frame = <50>;
		};
	};
};




